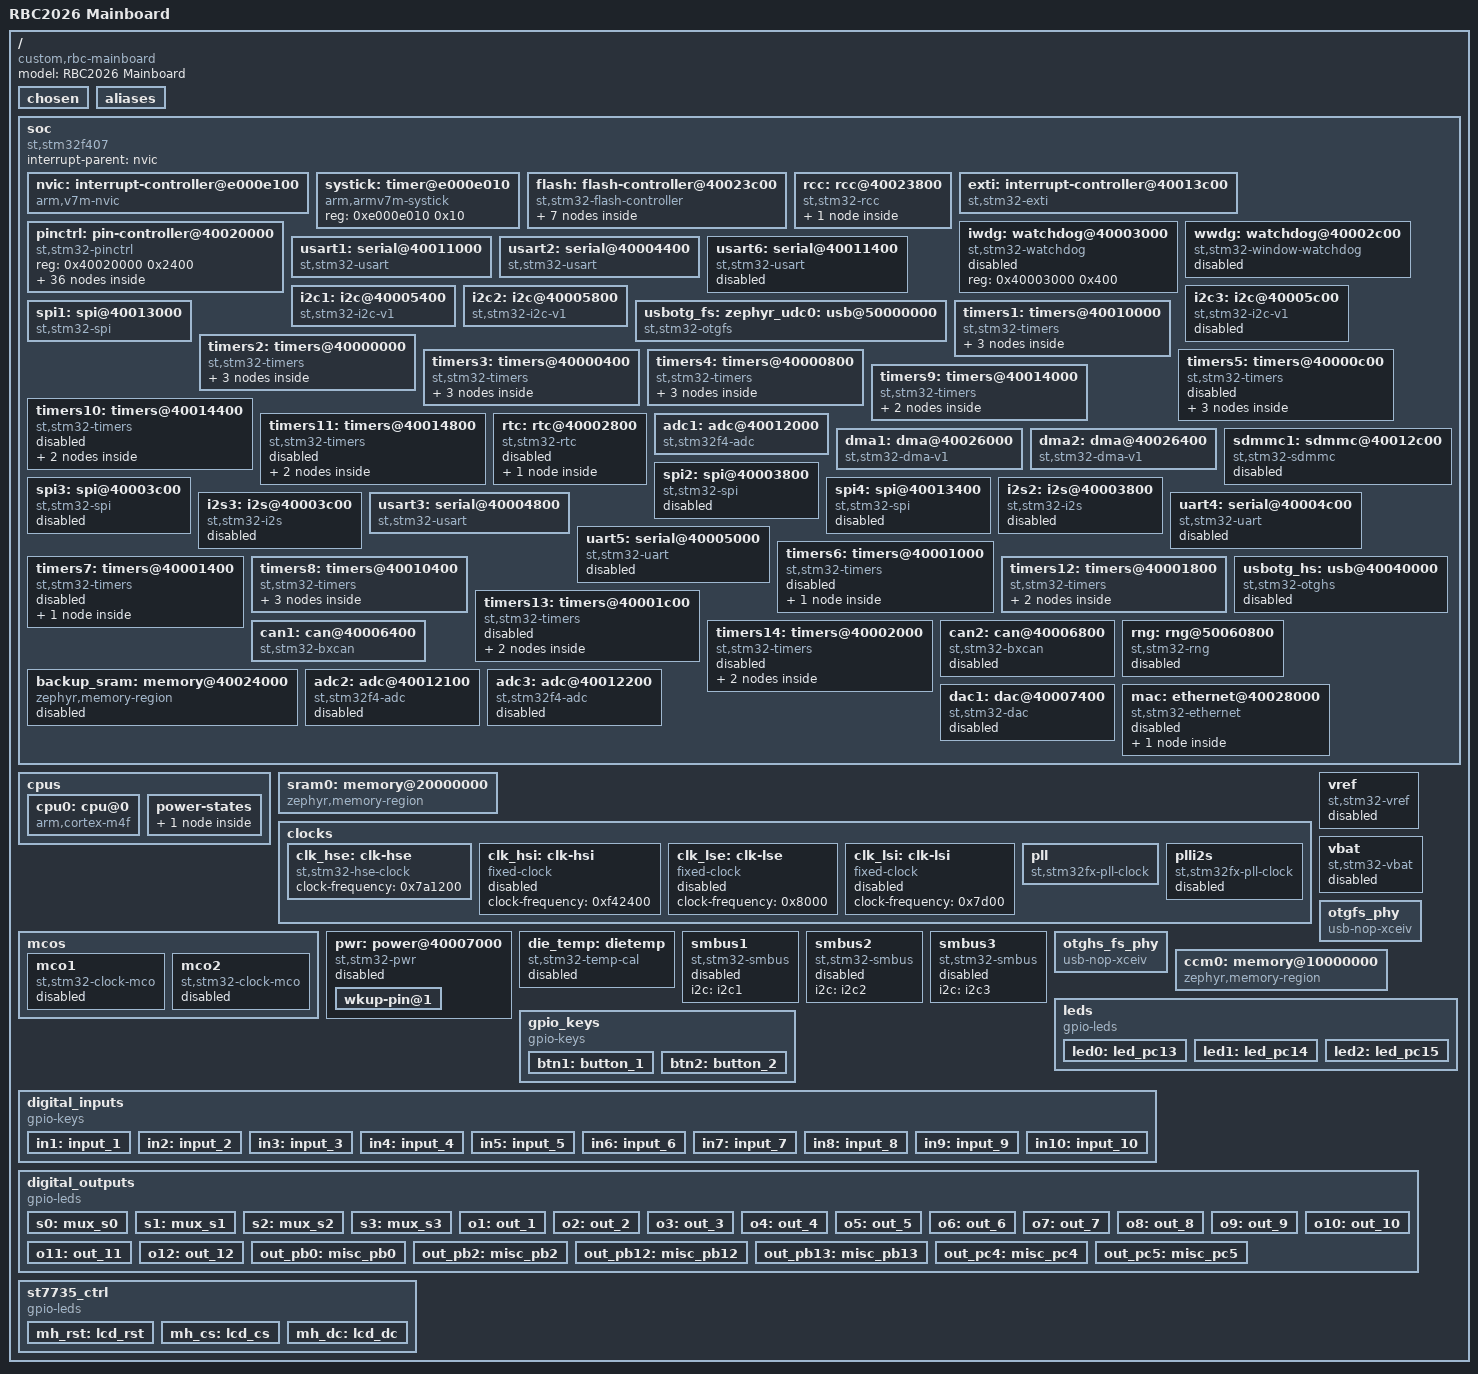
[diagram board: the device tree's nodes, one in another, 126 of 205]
/dts-v1/;

/* node '/' defined in zephyr/dts/common/skeleton.dtsi:9 */
/ {
	#address-cells = < 0x1 >;            /* in zephyr/dts/common/skeleton.dtsi:10 */
	#size-cells = < 0x1 >;               /* in zephyr/dts/common/skeleton.dtsi:11 */
	model = "RBC2026 Mainboard";         /* in rbc_main_zephyr/boards/rbc_mainboard/rbc_mainboard.dts:16 */
	compatible = "custom,rbc-mainboard"; /* in rbc_main_zephyr/boards/rbc_mainboard/rbc_mainboard.dts:17 */

	/* node '/chosen' defined in zephyr/dts/common/skeleton.dtsi:13 */
	chosen {
		zephyr,flash-controller = &flash;     /* in zephyr/dts/arm/st/f4/stm32f4.dtsi:26 */
		zephyr,system-timer-companion = &rtc; /* in zephyr/dts/arm/st/f4/stm32f4.dtsi:27 */
		zephyr,entropy = &rng;                /* in zephyr/dts/arm/st/f4/stm32f405.dtsi:13 */
		zephyr,console = &usart1;             /* in rbc_main_zephyr/boards/rbc_mainboard/rbc_mainboard.dts:20 */
		zephyr,shell-uart = &usart1;          /* in rbc_main_zephyr/boards/rbc_mainboard/rbc_mainboard.dts:21 */
		zephyr,sram = &sram0;                 /* in rbc_main_zephyr/boards/rbc_mainboard/rbc_mainboard.dts:22 */
		zephyr,flash = &flash0;               /* in rbc_main_zephyr/boards/rbc_mainboard/rbc_mainboard.dts:23 */
		zephyr,dtcm = &ccm0;                  /* in rbc_main_zephyr/boards/rbc_mainboard/rbc_mainboard.dts:24 */
		zephyr,canbus = &can1;                /* in rbc_main_zephyr/boards/rbc_mainboard/rbc_mainboard.dts:25 */
	};

	/* node '/aliases' defined in zephyr/dts/common/skeleton.dtsi:15 */
	aliases {
		led0 = &led0; /* in rbc_main_zephyr/boards/rbc_mainboard/rbc_mainboard.dts:190 */
		led1 = &led1; /* in rbc_main_zephyr/boards/rbc_mainboard/rbc_mainboard.dts:191 */
		led2 = &led2; /* in rbc_main_zephyr/boards/rbc_mainboard/rbc_mainboard.dts:192 */
		sw0 = &btn1;  /* in rbc_main_zephyr/boards/rbc_mainboard/rbc_mainboard.dts:193 */
		sw1 = &btn2;  /* in rbc_main_zephyr/boards/rbc_mainboard/rbc_mainboard.dts:194 */
	};

	/* node '/soc' defined in zephyr/dts/arm/armv7-m.dtsi:6 */
	soc {
		#address-cells = < 0x1 >;     /* in zephyr/dts/arm/armv7-m.dtsi:7 */
		#size-cells = < 0x1 >;        /* in zephyr/dts/arm/armv7-m.dtsi:8 */
		interrupt-parent = < &nvic >; /* in zephyr/dts/arm/armv7-m.dtsi:10 */
		ranges;                       /* in zephyr/dts/arm/armv7-m.dtsi:11 */
		compatible = "st,stm32f407",
		             "st,stm32f4",
		             "simple-bus";    /* in zephyr/dts/arm/st/f4/stm32f407.dtsi:11 */

		/* node '/soc/interrupt-controller@e000e100' defined in zephyr/dts/arm/armv7-m.dtsi:13 */
		nvic: interrupt-controller@e000e100 {
			#address-cells = < 0x1 >;            /* in zephyr/dts/arm/armv7-m.dtsi:14 */
			compatible = "arm,v7m-nvic";         /* in zephyr/dts/arm/armv7-m.dtsi:15 */
			reg = < 0xe000e100 0xc00 >;          /* in zephyr/dts/arm/armv7-m.dtsi:16 */
			interrupt-controller;                /* in zephyr/dts/arm/armv7-m.dtsi:17 */
			#interrupt-cells = < 0x2 >;          /* in zephyr/dts/arm/armv7-m.dtsi:18 */
			arm,num-irq-priority-bits = < 0x4 >; /* in zephyr/dts/arm/st/f4/stm32f4.dtsi:729 */
			phandle = < 0x1 >;                   /* in zephyr/dts/arm/armv7-m.dtsi:10 */
		};

		/* node '/soc/timer@e000e010' defined in zephyr/dts/arm/armv7-m.dtsi:21 */
		systick: timer@e000e010 {
			compatible = "arm,armv7m-systick"; /* in zephyr/dts/arm/armv7-m.dtsi:22 */
			reg = < 0xe000e010 0x10 >;         /* in zephyr/dts/arm/armv7-m.dtsi:23 */
		};

		/* node '/soc/flash-controller@40023c00' defined in zephyr/dts/arm/st/f4/stm32f4.dtsi:112 */
		flash: flash-controller@40023c00 {
			compatible = "st,stm32-flash-controller",
			             "st,stm32f4-flash-controller"; /* in zephyr/dts/arm/st/f4/stm32f4.dtsi:113 */
			reg = < 0x40023c00 0x400 >;                 /* in zephyr/dts/arm/st/f4/stm32f4.dtsi:114 */
			interrupts = < 0x4 0x0 >;                   /* in zephyr/dts/arm/st/f4/stm32f4.dtsi:115 */
			#address-cells = < 0x1 >;                   /* in zephyr/dts/arm/st/f4/stm32f4.dtsi:117 */
			#size-cells = < 0x1 >;                      /* in zephyr/dts/arm/st/f4/stm32f4.dtsi:118 */
			ranges;                                     /* in zephyr/dts/arm/st/f4/stm32f4.dtsi:119 */

			/* node '/soc/flash-controller@40023c00/flash@8000000' defined in zephyr/dts/arm/st/f4/stm32f4.dtsi:121 */
			flash0: flash@8000000 {
				compatible = "st,stm32f4-nv-flash",
				             "st,stm32-nv-flash",
				             "soc-nv-flash";         /* in zephyr/dts/arm/st/f4/stm32f4.dtsi:122 */
				#address-cells = < 0x1 >;            /* in zephyr/dts/arm/st/f4/stm32f4.dtsi:124 */
				#size-cells = < 0x1 >;               /* in zephyr/dts/arm/st/f4/stm32f4.dtsi:125 */
				write-block-size = < 0x1 >;          /* in zephyr/dts/arm/st/f4/stm32f4.dtsi:126 */
				max-erase-time = < 0xfa0 >;          /* in zephyr/dts/arm/st/f4/stm32f4.dtsi:128 */
				reg = < 0x8000000 0x100000 >;        /* in zephyr/dts/arm/st/f4/stm32f407Xg.dtsi:23 */
				ranges = < 0x0 0x8000000 0x100000 >; /* in zephyr/dts/arm/st/f4/stm32f407Xg.dtsi:24 */
			};

			/* node '/soc/flash-controller@40023c00/flash@1fff7800' defined in zephyr/dts/arm/st/f4/stm32f4.dtsi:131 */
			st_nvm_user_otp: flash@1fff7800 {
				compatible = "st,stm32-nvm-otp"; /* in zephyr/dts/arm/st/f4/stm32f4.dtsi:132 */
				reg = < 0x1fff7800 0x200 >;      /* in zephyr/dts/arm/st/f4/stm32f4.dtsi:133 */
				status = "disabled";             /* in zephyr/dts/arm/st/f4/stm32f4.dtsi:134 */
			};

			/* node '/soc/flash-controller@40023c00/flash@1fff7a00' defined in zephyr/dts/arm/st/f4/stm32f4.dtsi:148 */
			flash@1fff7a00 {
				compatible = "st,stm32-nvm-otp"; /* in zephyr/dts/arm/st/f4/stm32f4.dtsi:149 */
				reg = < 0x1fff7a00 0x100 >;      /* in zephyr/dts/arm/st/f4/stm32f4.dtsi:150 */

				/* node '/soc/flash-controller@40023c00/flash@1fff7a00/nvmem-layout' defined in zephyr/dts/arm/st/f4/stm32f4.dtsi:152 */
				nvmem-layout {
					compatible = "fixed-layout"; /* in zephyr/dts/arm/st/f4/stm32f4.dtsi:153 */
					#address-cells = < 0x1 >;    /* in zephyr/dts/arm/st/f4/stm32f4.dtsi:154 */
					#size-cells = < 0x1 >;       /* in zephyr/dts/arm/st/f4/stm32f4.dtsi:155 */

					/* node '/soc/flash-controller@40023c00/flash@1fff7a00/nvmem-layout/vrefint@2a' defined in zephyr/dts/arm/st/f4/stm32f4.dtsi:157 */
					vrefint_otp: vrefint@2a {
						reg = < 0x2a 0x2 >;          /* in zephyr/dts/arm/st/f4/stm32f4.dtsi:158 */
						#nvmem-cell-cells = < 0x0 >; /* in zephyr/dts/arm/st/f4/stm32f4.dtsi:159 */
						read-only;                   /* in zephyr/dts/arm/st/f4/stm32f4.dtsi:160 */
						phandle = < 0x29 >;          /* in zephyr/dts/arm/st/f4/stm32f4.dtsi:685 */
					};

					/* node '/soc/flash-controller@40023c00/flash@1fff7a00/nvmem-layout/ts-cal1@2c' defined in zephyr/dts/arm/st/f4/stm32f4.dtsi:163 */
					ts_cal1_otp: ts-cal1@2c {
						reg = < 0x2c 0x2 >;          /* in zephyr/dts/arm/st/f4/stm32f4.dtsi:164 */
						#nvmem-cell-cells = < 0x0 >; /* in zephyr/dts/arm/st/f4/stm32f4.dtsi:165 */
						read-only;                   /* in zephyr/dts/arm/st/f4/stm32f4.dtsi:166 */
						phandle = < 0x26 >;          /* in zephyr/dts/arm/st/f4/stm32f4.dtsi:674 */
					};

					/* node '/soc/flash-controller@40023c00/flash@1fff7a00/nvmem-layout/ts-cal2@2e' defined in zephyr/dts/arm/st/f4/stm32f4.dtsi:169 */
					ts_cal2_otp: ts-cal2@2e {
						reg = < 0x2e 0x2 >;          /* in zephyr/dts/arm/st/f4/stm32f4.dtsi:170 */
						#nvmem-cell-cells = < 0x0 >; /* in zephyr/dts/arm/st/f4/stm32f4.dtsi:171 */
						read-only;                   /* in zephyr/dts/arm/st/f4/stm32f4.dtsi:172 */
						phandle = < 0x27 >;          /* in zephyr/dts/arm/st/f4/stm32f4.dtsi:674 */
					};
				};
			};
		};

		/* node '/soc/rcc@40023800' defined in zephyr/dts/arm/st/f4/stm32f4.dtsi:178 */
		rcc: rcc@40023800 {
			#clock-cells = < 0x2 >;          /* in zephyr/dts/arm/st/f4/stm32f4.dtsi:180 */
			reg = < 0x40023800 0x400 >;      /* in zephyr/dts/arm/st/f4/stm32f4.dtsi:181 */
			compatible = "st,stm32-rcc";     /* in zephyr/dts/arm/st/f4/stm32f405.dtsi:20 */
			clocks = < &pll >;               /* in rbc_main_zephyr/boards/rbc_mainboard/rbc_mainboard.dts:220 */
			clock-frequency = < 0x8954400 >; /* in rbc_main_zephyr/boards/rbc_mainboard/rbc_mainboard.dts:221 */
			ahb-prescaler = < 0x1 >;         /* in rbc_main_zephyr/boards/rbc_mainboard/rbc_mainboard.dts:222 */
			apb1-prescaler = < 0x4 >;        /* in rbc_main_zephyr/boards/rbc_mainboard/rbc_mainboard.dts:223 */
			apb2-prescaler = < 0x2 >;        /* in rbc_main_zephyr/boards/rbc_mainboard/rbc_mainboard.dts:224 */
			phandle = < 0x3 >;               /* in zephyr/dts/arm/st/f4/stm32f4.dtsi:195 */

			/* node '/soc/rcc@40023800/reset-controller' defined in zephyr/dts/arm/st/f4/stm32f4.dtsi:183 */
			rctl: reset-controller {
				compatible = "st,stm32-rcc-rctl"; /* in zephyr/dts/arm/st/f4/stm32f4.dtsi:184 */
				#reset-cells = < 0x1 >;           /* in zephyr/dts/arm/st/f4/stm32f4.dtsi:185 */
				phandle = < 0x4 >;                /* in zephyr/dts/arm/st/f4/stm32f4.dtsi:294 */
			};
		};

		/* node '/soc/interrupt-controller@40013c00' defined in zephyr/dts/arm/st/f4/stm32f4.dtsi:189 */
		exti: interrupt-controller@40013c00 {
			compatible = "st,stm32-exti";  /* in zephyr/dts/arm/st/f4/stm32f4.dtsi:190 */
			interrupt-controller;          /* in zephyr/dts/arm/st/f4/stm32f4.dtsi:191 */
			#interrupt-cells = < 0x1 >;    /* in zephyr/dts/arm/st/f4/stm32f4.dtsi:192 */
			#address-cells = < 0x0 >;      /* in zephyr/dts/arm/st/f4/stm32f4.dtsi:193 */
			reg = < 0x40013c00 0x400 >;    /* in zephyr/dts/arm/st/f4/stm32f4.dtsi:194 */
			clocks = < &rcc 0x44 0x4000 >; /* in zephyr/dts/arm/st/f4/stm32f4.dtsi:195 */
			num-lines = < 0x20 >;          /* in zephyr/dts/arm/st/f4/stm32f4.dtsi:196 */
			interrupts = < 0x6 0x0 >,
			             < 0x7 0x0 >,
			             < 0x8 0x0 >,
			             < 0x9 0x0 >,
			             < 0xa 0x0 >,
			             < 0x17 0x0 >,
			             < 0x28 0x0 >;     /* in zephyr/dts/arm/st/f4/stm32f4.dtsi:197 */
			interrupt-names = "line0",
			                  "line1",
			                  "line2",
			                  "line3",
			                  "line4",
			                  "line5-9",
			                  "line10-15"; /* in zephyr/dts/arm/st/f4/stm32f4.dtsi:199 */
			line-ranges = < 0x0 0x1 >,
			              < 0x1 0x1 >,
			              < 0x2 0x1 >,
			              < 0x3 0x1 >,
			              < 0x4 0x1 >,
			              < 0x5 0x5 >,
			              < 0xa 0x6 >;     /* in zephyr/dts/arm/st/f4/stm32f4.dtsi:201 */
		};

		/* node '/soc/pin-controller@40020000' defined in zephyr/dts/arm/st/f4/stm32f4.dtsi:205 */
		pinctrl: pin-controller@40020000 {
			compatible = "st,stm32-pinctrl"; /* in zephyr/dts/arm/st/f4/stm32f4.dtsi:206 */
			#address-cells = < 0x1 >;        /* in zephyr/dts/arm/st/f4/stm32f4.dtsi:207 */
			#size-cells = < 0x1 >;           /* in zephyr/dts/arm/st/f4/stm32f4.dtsi:208 */
			reg = < 0x40020000 0x2400 >;     /* in zephyr/dts/arm/st/f4/stm32f405.dtsi:24 */

			/* node '/soc/pin-controller@40020000/gpio@40020000' defined in zephyr/dts/arm/st/f4/stm32f4.dtsi:211 */
			gpioa: gpio@40020000 {
				compatible = "st,stm32-gpio"; /* in zephyr/dts/arm/st/f4/stm32f4.dtsi:212 */
				gpio-controller;              /* in zephyr/dts/arm/st/f4/stm32f4.dtsi:213 */
				#gpio-cells = < 0x2 >;        /* in zephyr/dts/arm/st/f4/stm32f4.dtsi:214 */
				reg = < 0x40020000 0x400 >;   /* in zephyr/dts/arm/st/f4/stm32f4.dtsi:215 */
				clocks = < &rcc 0x30 0x1 >;   /* in zephyr/dts/arm/st/f4/stm32f4.dtsi:216 */
				phandle = < 0x25 >;           /* in zephyr/dts/arm/st/f4/stm32f4.dtsi:668 */
			};

			/* node '/soc/pin-controller@40020000/gpio@40020400' defined in zephyr/dts/arm/st/f4/stm32f4.dtsi:219 */
			gpiob: gpio@40020400 {
				compatible = "st,stm32-gpio"; /* in zephyr/dts/arm/st/f4/stm32f4.dtsi:220 */
				gpio-controller;              /* in zephyr/dts/arm/st/f4/stm32f4.dtsi:221 */
				#gpio-cells = < 0x2 >;        /* in zephyr/dts/arm/st/f4/stm32f4.dtsi:222 */
				reg = < 0x40020400 0x400 >;   /* in zephyr/dts/arm/st/f4/stm32f4.dtsi:223 */
				clocks = < &rcc 0x30 0x2 >;   /* in zephyr/dts/arm/st/f4/stm32f4.dtsi:224 */
				phandle = < 0x30 >;           /* in rbc_main_zephyr/boards/rbc_mainboard/rbc_mainboard.dts:103 */
			};

			/* node '/soc/pin-controller@40020000/gpio@40020800' defined in zephyr/dts/arm/st/f4/stm32f4.dtsi:227 */
			gpioc: gpio@40020800 {
				compatible = "st,stm32-gpio"; /* in zephyr/dts/arm/st/f4/stm32f4.dtsi:228 */
				gpio-controller;              /* in zephyr/dts/arm/st/f4/stm32f4.dtsi:229 */
				#gpio-cells = < 0x2 >;        /* in zephyr/dts/arm/st/f4/stm32f4.dtsi:230 */
				reg = < 0x40020800 0x400 >;   /* in zephyr/dts/arm/st/f4/stm32f4.dtsi:231 */
				clocks = < &rcc 0x30 0x4 >;   /* in zephyr/dts/arm/st/f4/stm32f4.dtsi:232 */
				phandle = < 0x2d >;           /* in rbc_main_zephyr/boards/rbc_mainboard/rbc_mainboard.dts:37 */
			};

			/* node '/soc/pin-controller@40020000/gpio@40020c00' defined in zephyr/dts/arm/st/f4/stm32f4.dtsi:235 */
			gpiod: gpio@40020c00 {
				compatible = "st,stm32-gpio"; /* in zephyr/dts/arm/st/f4/stm32f4.dtsi:236 */
				gpio-controller;              /* in zephyr/dts/arm/st/f4/stm32f4.dtsi:237 */
				#gpio-cells = < 0x2 >;        /* in zephyr/dts/arm/st/f4/stm32f4.dtsi:238 */
				reg = < 0x40020c00 0x400 >;   /* in zephyr/dts/arm/st/f4/stm32f4.dtsi:239 */
				clocks = < &rcc 0x30 0x8 >;   /* in zephyr/dts/arm/st/f4/stm32f4.dtsi:240 */
				phandle = < 0x2f >;           /* in rbc_main_zephyr/boards/rbc_mainboard/rbc_mainboard.dts:98 */
			};

			/* node '/soc/pin-controller@40020000/gpio@40021000' defined in zephyr/dts/arm/st/f4/stm32f4.dtsi:243 */
			gpioe: gpio@40021000 {
				compatible = "st,stm32-gpio"; /* in zephyr/dts/arm/st/f4/stm32f4.dtsi:244 */
				gpio-controller;              /* in zephyr/dts/arm/st/f4/stm32f4.dtsi:245 */
				#gpio-cells = < 0x2 >;        /* in zephyr/dts/arm/st/f4/stm32f4.dtsi:246 */
				reg = < 0x40021000 0x400 >;   /* in zephyr/dts/arm/st/f4/stm32f4.dtsi:247 */
				clocks = < &rcc 0x30 0x10 >;  /* in zephyr/dts/arm/st/f4/stm32f4.dtsi:248 */
				phandle = < 0x2e >;           /* in rbc_main_zephyr/boards/rbc_mainboard/rbc_mainboard.dts:62 */
			};

			/* node '/soc/pin-controller@40020000/gpio@40021400' defined in zephyr/dts/arm/st/f4/stm32f4.dtsi:251 */
			gpiof: gpio@40021400 {
				compatible = "st,stm32-gpio"; /* in zephyr/dts/arm/st/f4/stm32f405.dtsi:27 */
				gpio-controller;              /* in zephyr/dts/arm/st/f4/stm32f405.dtsi:28 */
				#gpio-cells = < 0x2 >;        /* in zephyr/dts/arm/st/f4/stm32f405.dtsi:29 */
				reg = < 0x40021400 0x400 >;   /* in zephyr/dts/arm/st/f4/stm32f405.dtsi:30 */
				clocks = < &rcc 0x30 0x20 >;  /* in zephyr/dts/arm/st/f4/stm32f405.dtsi:31 */
			};

			/* node '/soc/pin-controller@40020000/gpio@40021800' defined in zephyr/dts/arm/st/f4/stm32f4.dtsi:259 */
			gpiog: gpio@40021800 {
				compatible = "st,stm32-gpio"; /* in zephyr/dts/arm/st/f4/stm32f405.dtsi:35 */
				gpio-controller;              /* in zephyr/dts/arm/st/f4/stm32f405.dtsi:36 */
				#gpio-cells = < 0x2 >;        /* in zephyr/dts/arm/st/f4/stm32f405.dtsi:37 */
				reg = < 0x40021800 0x400 >;   /* in zephyr/dts/arm/st/f4/stm32f405.dtsi:38 */
				clocks = < &rcc 0x30 0x40 >;  /* in zephyr/dts/arm/st/f4/stm32f405.dtsi:39 */
			};

			/* node '/soc/pin-controller@40020000/gpio@40021c00' defined in zephyr/dts/arm/st/f4/stm32f4.dtsi:267 */
			gpioh: gpio@40021c00 {
				compatible = "st,stm32-gpio"; /* in zephyr/dts/arm/st/f4/stm32f4.dtsi:268 */
				gpio-controller;              /* in zephyr/dts/arm/st/f4/stm32f4.dtsi:269 */
				#gpio-cells = < 0x2 >;        /* in zephyr/dts/arm/st/f4/stm32f4.dtsi:270 */
				reg = < 0x40021c00 0x400 >;   /* in zephyr/dts/arm/st/f4/stm32f4.dtsi:271 */
				clocks = < &rcc 0x30 0x80 >;  /* in zephyr/dts/arm/st/f4/stm32f4.dtsi:272 */
			};

			/* node '/soc/pin-controller@40020000/gpio@40022000' defined in zephyr/dts/arm/st/f4/stm32f405.dtsi:42 */
			gpioi: gpio@40022000 {
				compatible = "st,stm32-gpio"; /* in zephyr/dts/arm/st/f4/stm32f405.dtsi:43 */
				gpio-controller;              /* in zephyr/dts/arm/st/f4/stm32f405.dtsi:44 */
				#gpio-cells = < 0x2 >;        /* in zephyr/dts/arm/st/f4/stm32f405.dtsi:45 */
				reg = < 0x40022000 0x400 >;   /* in zephyr/dts/arm/st/f4/stm32f405.dtsi:46 */
				clocks = < &rcc 0x30 0x100 >; /* in zephyr/dts/arm/st/f4/stm32f405.dtsi:47 */
			};

			/* node '/soc/pin-controller@40020000/adc1_in0_pa0' defined in modules/hal/stm32/dts/st/f4/stm32f407v(e-g)tx-pinctrl.dtsi:13 */
			adc1_in0_pa0: adc1_in0_pa0 {
				pinmux = < 0x10 >;  /* in modules/hal/stm32/dts/st/f4/stm32f407v(e-g)tx-pinctrl.dtsi:14 */
				phandle = < 0x1a >; /* in rbc_main_zephyr/boards/rbc_mainboard/rbc_mainboard.dts:319 */
			};

			/* node '/soc/pin-controller@40020000/can1_rx_pd0' defined in modules/hal/stm32/dts/st/f4/stm32f407v(e-g)tx-pinctrl.dtsi:515 */
			can1_rx_pd0: can1_rx_pd0 {
				pinmux = < 0x609 >; /* in modules/hal/stm32/dts/st/f4/stm32f407v(e-g)tx-pinctrl.dtsi:516 */
				bias-pull-up;       /* in modules/hal/stm32/dts/st/f4/stm32f407v(e-g)tx-pinctrl.dtsi:517 */
				phandle = < 0x21 >; /* in rbc_main_zephyr/boards/rbc_mainboard/rbc_mainboard.dts:270 */
			};

			/* node '/soc/pin-controller@40020000/can1_tx_pd1' defined in modules/hal/stm32/dts/st/f4/stm32f407v(e-g)tx-pinctrl.dtsi:540 */
			can1_tx_pd1: can1_tx_pd1 {
				pinmux = < 0x629 >; /* in modules/hal/stm32/dts/st/f4/stm32f407v(e-g)tx-pinctrl.dtsi:541 */
				phandle = < 0x22 >; /* in rbc_main_zephyr/boards/rbc_mainboard/rbc_mainboard.dts:270 */
			};

			/* node '/soc/pin-controller@40020000/i2c1_scl_pb6' defined in modules/hal/stm32/dts/st/f4/stm32f407v(e-g)tx-pinctrl.dtsi:783 */
			i2c1_scl_pb6: i2c1_scl_pb6 {
				pinmux = < 0x2c4 >; /* in modules/hal/stm32/dts/st/f4/stm32f407v(e-g)tx-pinctrl.dtsi:784 */
				bias-pull-up;       /* in modules/hal/stm32/dts/st/f4/stm32f407v(e-g)tx-pinctrl.dtsi:785 */
				drive-open-drain;   /* in modules/hal/stm32/dts/st/f4/stm32f407v(e-g)tx-pinctrl.dtsi:786 */
				phandle = < 0x9 >;  /* in rbc_main_zephyr/boards/rbc_mainboard/rbc_mainboard.dts:284 */
			};

			/* node '/soc/pin-controller@40020000/i2c2_scl_pb10' defined in modules/hal/stm32/dts/st/f4/stm32f407v(e-g)tx-pinctrl.dtsi:795 */
			i2c2_scl_pb10: i2c2_scl_pb10 {
				pinmux = < 0x344 >; /* in modules/hal/stm32/dts/st/f4/stm32f407v(e-g)tx-pinctrl.dtsi:796 */
				bias-pull-up;       /* in modules/hal/stm32/dts/st/f4/stm32f407v(e-g)tx-pinctrl.dtsi:797 */
				drive-open-drain;   /* in modules/hal/stm32/dts/st/f4/stm32f407v(e-g)tx-pinctrl.dtsi:798 */
				phandle = < 0xb >;  /* in rbc_main_zephyr/boards/rbc_mainboard/rbc_mainboard.dts:296 */
			};

			/* node '/soc/pin-controller@40020000/i2c1_sda_pb7' defined in modules/hal/stm32/dts/st/f4/stm32f407v(e-g)tx-pinctrl.dtsi:809 */
			i2c1_sda_pb7: i2c1_sda_pb7 {
				pinmux = < 0x2e4 >; /* in modules/hal/stm32/dts/st/f4/stm32f407v(e-g)tx-pinctrl.dtsi:810 */
				bias-pull-up;       /* in modules/hal/stm32/dts/st/f4/stm32f407v(e-g)tx-pinctrl.dtsi:811 */
				drive-open-drain;   /* in modules/hal/stm32/dts/st/f4/stm32f407v(e-g)tx-pinctrl.dtsi:812 */
				phandle = < 0xa >;  /* in rbc_main_zephyr/boards/rbc_mainboard/rbc_mainboard.dts:284 */
			};

			/* node '/soc/pin-controller@40020000/i2c2_sda_pb11' defined in modules/hal/stm32/dts/st/f4/stm32f407v(e-g)tx-pinctrl.dtsi:821 */
			i2c2_sda_pb11: i2c2_sda_pb11 {
				pinmux = < 0x364 >; /* in modules/hal/stm32/dts/st/f4/stm32f407v(e-g)tx-pinctrl.dtsi:822 */
				bias-pull-up;       /* in modules/hal/stm32/dts/st/f4/stm32f407v(e-g)tx-pinctrl.dtsi:823 */
				drive-open-drain;   /* in modules/hal/stm32/dts/st/f4/stm32f407v(e-g)tx-pinctrl.dtsi:824 */
				phandle = < 0xc >;  /* in rbc_main_zephyr/boards/rbc_mainboard/rbc_mainboard.dts:296 */
			};

			/* node '/soc/pin-controller@40020000/spi1_miso_pa6' defined in modules/hal/stm32/dts/st/f4/stm32f407v(e-g)tx-pinctrl.dtsi:1018 */
			spi1_miso_pa6: spi1_miso_pa6 {
				pinmux = < 0xc5 >;             /* in modules/hal/stm32/dts/st/f4/stm32f407v(e-g)tx-pinctrl.dtsi:1019 */
				bias-pull-down;                /* in modules/hal/stm32/dts/st/f4/stm32f407v(e-g)tx-pinctrl.dtsi:1020 */
				slew-rate = "very-high-speed"; /* in modules/hal/stm32/dts/st/f4/stm32f407v(e-g)tx-pinctrl.dtsi:1021 */
				phandle = < 0xe >;             /* in rbc_main_zephyr/boards/rbc_mainboard/rbc_mainboard.dts:308 */
			};

			/* node '/soc/pin-controller@40020000/spi1_mosi_pa7' defined in modules/hal/stm32/dts/st/f4/stm32f407v(e-g)tx-pinctrl.dtsi:1056 */
			spi1_mosi_pa7: spi1_mosi_pa7 {
				pinmux = < 0xe5 >;             /* in modules/hal/stm32/dts/st/f4/stm32f407v(e-g)tx-pinctrl.dtsi:1057 */
				bias-pull-down;                /* in modules/hal/stm32/dts/st/f4/stm32f407v(e-g)tx-pinctrl.dtsi:1058 */
				slew-rate = "very-high-speed"; /* in modules/hal/stm32/dts/st/f4/stm32f407v(e-g)tx-pinctrl.dtsi:1059 */
				phandle = < 0xf >;             /* in rbc_main_zephyr/boards/rbc_mainboard/rbc_mainboard.dts:308 */
			};

			/* node '/soc/pin-controller@40020000/spi1_sck_pa5' defined in modules/hal/stm32/dts/st/f4/stm32f407v(e-g)tx-pinctrl.dtsi:1132 */
			spi1_sck_pa5: spi1_sck_pa5 {
				pinmux = < 0xa5 >;             /* in modules/hal/stm32/dts/st/f4/stm32f407v(e-g)tx-pinctrl.dtsi:1133 */
				bias-pull-down;                /* in modules/hal/stm32/dts/st/f4/stm32f407v(e-g)tx-pinctrl.dtsi:1134 */
				slew-rate = "very-high-speed"; /* in modules/hal/stm32/dts/st/f4/stm32f407v(e-g)tx-pinctrl.dtsi:1135 */
				phandle = < 0xd >;             /* in rbc_main_zephyr/boards/rbc_mainboard/rbc_mainboard.dts:308 */
			};

			/* node '/soc/pin-controller@40020000/tim2_ch1_pa15' defined in modules/hal/stm32/dts/st/f4/stm32f407v(e-g)tx-pinctrl.dtsi:1284 */
			tim2_ch1_pa15: tim2_ch1_pa15 {
				pinmux = < 0x1e1 >; /* in modules/hal/stm32/dts/st/f4/stm32f407v(e-g)tx-pinctrl.dtsi:1285 */
				phandle = < 0x13 >; /* in rbc_main_zephyr/boards/rbc_mainboard/rbc_mainboard.dts:338 */
			};

			/* node '/soc/pin-controller@40020000/tim2_ch2_pb3' defined in modules/hal/stm32/dts/st/f4/stm32f407v(e-g)tx-pinctrl.dtsi:1288 */
			tim2_ch2_pb3: tim2_ch2_pb3 {
				pinmux = < 0x261 >; /* in modules/hal/stm32/dts/st/f4/stm32f407v(e-g)tx-pinctrl.dtsi:1289 */
				phandle = < 0x14 >; /* in rbc_main_zephyr/boards/rbc_mainboard/rbc_mainboard.dts:338 */
			};

			/* node '/soc/pin-controller@40020000/tim12_ch1_pb14' defined in modules/hal/stm32/dts/st/f4/stm32f407v(e-g)tx-pinctrl.dtsi:1300 */
			tim12_ch1_pb14: tim12_ch1_pb14 {
				pinmux = < 0x3c9 >; /* in modules/hal/stm32/dts/st/f4/stm32f407v(e-g)tx-pinctrl.dtsi:1301 */
				phandle = < 0x1e >; /* in rbc_main_zephyr/boards/rbc_mainboard/rbc_mainboard.dts:436 */
			};

			/* node '/soc/pin-controller@40020000/tim12_ch2_pb15' defined in modules/hal/stm32/dts/st/f4/stm32f407v(e-g)tx-pinctrl.dtsi:1304 */
			tim12_ch2_pb15: tim12_ch2_pb15 {
				pinmux = < 0x3e9 >; /* in modules/hal/stm32/dts/st/f4/stm32f407v(e-g)tx-pinctrl.dtsi:1305 */
				phandle = < 0x1f >; /* in rbc_main_zephyr/boards/rbc_mainboard/rbc_mainboard.dts:436 */
			};

			/* node '/soc/pin-controller@40020000/tim3_ch1_pc6' defined in modules/hal/stm32/dts/st/f4/stm32f407v(e-g)tx-pinctrl.dtsi:1336 */
			tim3_ch1_pc6: tim3_ch1_pc6 {
				pinmux = < 0x4c2 >; /* in modules/hal/stm32/dts/st/f4/stm32f407v(e-g)tx-pinctrl.dtsi:1337 */
				phandle = < 0x15 >; /* in rbc_main_zephyr/boards/rbc_mainboard/rbc_mainboard.dts:353 */
			};

			/* node '/soc/pin-controller@40020000/tim3_ch2_pc7' defined in modules/hal/stm32/dts/st/f4/stm32f407v(e-g)tx-pinctrl.dtsi:1340 */
			tim3_ch2_pc7: tim3_ch2_pc7 {
				pinmux = < 0x4e2 >; /* in modules/hal/stm32/dts/st/f4/stm32f407v(e-g)tx-pinctrl.dtsi:1341 */
				phandle = < 0x16 >; /* in rbc_main_zephyr/boards/rbc_mainboard/rbc_mainboard.dts:353 */
			};

			/* node '/soc/pin-controller@40020000/tim4_ch1_pd12' defined in modules/hal/stm32/dts/st/f4/stm32f407v(e-g)tx-pinctrl.dtsi:1372 */
			tim4_ch1_pd12: tim4_ch1_pd12 {
				pinmux = < 0x782 >; /* in modules/hal/stm32/dts/st/f4/stm32f407v(e-g)tx-pinctrl.dtsi:1373 */
				phandle = < 0x17 >; /* in rbc_main_zephyr/boards/rbc_mainboard/rbc_mainboard.dts:368 */
			};

			/* node '/soc/pin-controller@40020000/tim4_ch2_pd13' defined in modules/hal/stm32/dts/st/f4/stm32f407v(e-g)tx-pinctrl.dtsi:1376 */
			tim4_ch2_pd13: tim4_ch2_pd13 {
				pinmux = < 0x7a2 >; /* in modules/hal/stm32/dts/st/f4/stm32f407v(e-g)tx-pinctrl.dtsi:1377 */
				phandle = < 0x18 >; /* in rbc_main_zephyr/boards/rbc_mainboard/rbc_mainboard.dts:368 */
			};

			/* node '/soc/pin-controller@40020000/tim9_ch2_pe6' defined in modules/hal/stm32/dts/st/f4/stm32f407v(e-g)tx-pinctrl.dtsi:1456 */
			tim9_ch2_pe6: tim9_ch2_pe6 {
				pinmux = < 0x8c3 >; /* in modules/hal/stm32/dts/st/f4/stm32f407v(e-g)tx-pinctrl.dtsi:1457 */
				phandle = < 0x19 >; /* in rbc_main_zephyr/boards/rbc_mainboard/rbc_mainboard.dts:419 */
			};

			/* node '/soc/pin-controller@40020000/usart1_rx_pa10' defined in modules/hal/stm32/dts/st/f4/stm32f407v(e-g)tx-pinctrl.dtsi:1516 */
			usart1_rx_pa10: usart1_rx_pa10 {
				pinmux = < 0x147 >; /* in modules/hal/stm32/dts/st/f4/stm32f407v(e-g)tx-pinctrl.dtsi:1517 */
				phandle = < 0x6 >;  /* in rbc_main_zephyr/boards/rbc_mainboard/rbc_mainboard.dts:233 */
			};

			/* node '/soc/pin-controller@40020000/usart2_rx_pd6' defined in modules/hal/stm32/dts/st/f4/stm32f407v(e-g)tx-pinctrl.dtsi:1528 */
			usart2_rx_pd6: usart2_rx_pd6 {
				pinmux = < 0x6c7 >; /* in modules/hal/stm32/dts/st/f4/stm32f407v(e-g)tx-pinctrl.dtsi:1529 */
				phandle = < 0x8 >;  /* in rbc_main_zephyr/boards/rbc_mainboard/rbc_mainboard.dts:245 */
			};

			/* node '/soc/pin-controller@40020000/usart3_rx_pd9' defined in modules/hal/stm32/dts/st/f4/stm32f407v(e-g)tx-pinctrl.dtsi:1540 */
			usart3_rx_pd9: usart3_rx_pd9 {
				pinmux = < 0x727 >; /* in modules/hal/stm32/dts/st/f4/stm32f407v(e-g)tx-pinctrl.dtsi:1541 */
				phandle = < 0x1d >; /* in rbc_main_zephyr/boards/rbc_mainboard/rbc_mainboard.dts:257 */
			};

			/* node '/soc/pin-controller@40020000/usart1_tx_pa9' defined in modules/hal/stm32/dts/st/f4/stm32f407v(e-g)tx-pinctrl.dtsi:1562 */
			usart1_tx_pa9: usart1_tx_pa9 {
				pinmux = < 0x127 >; /* in modules/hal/stm32/dts/st/f4/stm32f407v(e-g)tx-pinctrl.dtsi:1563 */
				bias-pull-up;       /* in modules/hal/stm32/dts/st/f4/stm32f407v(e-g)tx-pinctrl.dtsi:1564 */
				phandle = < 0x5 >;  /* in rbc_main_zephyr/boards/rbc_mainboard/rbc_mainboard.dts:233 */
			};

			/* node '/soc/pin-controller@40020000/usart2_tx_pd5' defined in modules/hal/stm32/dts/st/f4/stm32f407v(e-g)tx-pinctrl.dtsi:1577 */
			usart2_tx_pd5: usart2_tx_pd5 {
				pinmux = < 0x6a7 >; /* in modules/hal/stm32/dts/st/f4/stm32f407v(e-g)tx-pinctrl.dtsi:1578 */
				bias-pull-up;       /* in modules/hal/stm32/dts/st/f4/stm32f407v(e-g)tx-pinctrl.dtsi:1579 */
				phandle = < 0x7 >;  /* in rbc_main_zephyr/boards/rbc_mainboard/rbc_mainboard.dts:245 */
			};

			/* node '/soc/pin-controller@40020000/usart3_tx_pd8' defined in modules/hal/stm32/dts/st/f4/stm32f407v(e-g)tx-pinctrl.dtsi:1592 */
			usart3_tx_pd8: usart3_tx_pd8 {
				pinmux = < 0x707 >; /* in modules/hal/stm32/dts/st/f4/stm32f407v(e-g)tx-pinctrl.dtsi:1593 */
				bias-pull-up;       /* in modules/hal/stm32/dts/st/f4/stm32f407v(e-g)tx-pinctrl.dtsi:1594 */
				phandle = < 0x1c >; /* in rbc_main_zephyr/boards/rbc_mainboard/rbc_mainboard.dts:257 */
			};

			/* node '/soc/pin-controller@40020000/usb_otg_fs_dm_pa11' defined in modules/hal/stm32/dts/st/f4/stm32f407v(e-g)tx-pinctrl.dtsi:1631 */
			usb_otg_fs_dm_pa11: usb_otg_fs_dm_pa11 {
				pinmux = < 0x16a >; /* in modules/hal/stm32/dts/st/f4/stm32f407v(e-g)tx-pinctrl.dtsi:1632 */
				phandle = < 0x11 >; /* in rbc_main_zephyr/boards/rbc_mainboard/rbc_mainboard.dts:448 */
			};

			/* node '/soc/pin-controller@40020000/usb_otg_fs_dp_pa12' defined in modules/hal/stm32/dts/st/f4/stm32f407v(e-g)tx-pinctrl.dtsi:1635 */
			usb_otg_fs_dp_pa12: usb_otg_fs_dp_pa12 {
				pinmux = < 0x18a >; /* in modules/hal/stm32/dts/st/f4/stm32f407v(e-g)tx-pinctrl.dtsi:1636 */
				phandle = < 0x12 >; /* in rbc_main_zephyr/boards/rbc_mainboard/rbc_mainboard.dts:448 */
			};
		};

		/* node '/soc/watchdog@40003000' defined in zephyr/dts/arm/st/f4/stm32f4.dtsi:276 */
		iwdg: watchdog@40003000 {
			compatible = "st,stm32-watchdog"; /* in zephyr/dts/arm/st/f4/stm32f4.dtsi:277 */
			reg = < 0x40003000 0x400 >;       /* in zephyr/dts/arm/st/f4/stm32f4.dtsi:278 */
			status = "disabled";              /* in zephyr/dts/arm/st/f4/stm32f4.dtsi:279 */
		};

		/* node '/soc/watchdog@40002c00' defined in zephyr/dts/arm/st/f4/stm32f4.dtsi:282 */
		wwdg: watchdog@40002c00 {
			compatible = "st,stm32-window-watchdog"; /* in zephyr/dts/arm/st/f4/stm32f4.dtsi:283 */
			reg = < 0x40002c00 0x400 >;              /* in zephyr/dts/arm/st/f4/stm32f4.dtsi:284 */
			clocks = < &rcc 0x40 0x800 >;            /* in zephyr/dts/arm/st/f4/stm32f4.dtsi:285 */
			interrupts = < 0x0 0x0 >;                /* in zephyr/dts/arm/st/f4/stm32f4.dtsi:286 */
			status = "disabled";                     /* in zephyr/dts/arm/st/f4/stm32f4.dtsi:287 */
		};

		/* node '/soc/serial@40011000' defined in zephyr/dts/arm/st/f4/stm32f4.dtsi:290 */
		usart1: serial@40011000 {
			compatible = "st,stm32-usart",
			             "st,stm32-uart";                   /* in zephyr/dts/arm/st/f4/stm32f4.dtsi:291 */
			reg = < 0x40011000 0x400 >;                     /* in zephyr/dts/arm/st/f4/stm32f4.dtsi:292 */
			clocks = < &rcc 0x44 0x10 >;                    /* in zephyr/dts/arm/st/f4/stm32f4.dtsi:293 */
			resets = < &rctl 0x484 >;                       /* in zephyr/dts/arm/st/f4/stm32f4.dtsi:294 */
			interrupts = < 0x25 0x0 >;                      /* in zephyr/dts/arm/st/f4/stm32f4.dtsi:295 */
			pinctrl-0 = < &usart1_tx_pa9 &usart1_rx_pa10 >; /* in rbc_main_zephyr/boards/rbc_mainboard/rbc_mainboard.dts:233 */
			pinctrl-names = "default";                      /* in rbc_main_zephyr/boards/rbc_mainboard/rbc_mainboard.dts:234 */
			current-speed = < 0x1c200 >;                    /* in rbc_main_zephyr/boards/rbc_mainboard/rbc_mainboard.dts:235 */
			status = "okay";                                /* in rbc_main_zephyr/boards/rbc_mainboard/rbc_mainboard.dts:236 */
		};

		/* node '/soc/serial@40004400' defined in zephyr/dts/arm/st/f4/stm32f4.dtsi:299 */
		usart2: serial@40004400 {
			compatible = "st,stm32-usart",
			             "st,stm32-uart";                  /* in zephyr/dts/arm/st/f4/stm32f4.dtsi:300 */
			reg = < 0x40004400 0x400 >;                    /* in zephyr/dts/arm/st/f4/stm32f4.dtsi:301 */
			clocks = < &rcc 0x40 0x20000 >;                /* in zephyr/dts/arm/st/f4/stm32f4.dtsi:302 */
			resets = < &rctl 0x411 >;                      /* in zephyr/dts/arm/st/f4/stm32f4.dtsi:303 */
			interrupts = < 0x26 0x0 >;                     /* in zephyr/dts/arm/st/f4/stm32f4.dtsi:304 */
			pinctrl-0 = < &usart2_tx_pd5 &usart2_rx_pd6 >; /* in rbc_main_zephyr/boards/rbc_mainboard/rbc_mainboard.dts:245 */
			pinctrl-names = "default";                     /* in rbc_main_zephyr/boards/rbc_mainboard/rbc_mainboard.dts:246 */
			current-speed = < 0x1c200 >;                   /* in rbc_main_zephyr/boards/rbc_mainboard/rbc_mainboard.dts:247 */
			status = "okay";                               /* in rbc_main_zephyr/boards/rbc_mainboard/rbc_mainboard.dts:248 */
		};

		/* node '/soc/serial@40011400' defined in zephyr/dts/arm/st/f4/stm32f4.dtsi:308 */
		usart6: serial@40011400 {
			compatible = "st,stm32-usart",
			             "st,stm32-uart";  /* in zephyr/dts/arm/st/f4/stm32f4.dtsi:309 */
			reg = < 0x40011400 0x400 >;    /* in zephyr/dts/arm/st/f4/stm32f4.dtsi:310 */
			clocks = < &rcc 0x44 0x20 >;   /* in zephyr/dts/arm/st/f4/stm32f4.dtsi:311 */
			resets = < &rctl 0x485 >;      /* in zephyr/dts/arm/st/f4/stm32f4.dtsi:312 */
			interrupts = < 0x47 0x0 >;     /* in zephyr/dts/arm/st/f4/stm32f4.dtsi:313 */
			status = "disabled";           /* in zephyr/dts/arm/st/f4/stm32f4.dtsi:314 */
		};

		/* node '/soc/i2c@40005400' defined in zephyr/dts/arm/st/f4/stm32f4.dtsi:317 */
		i2c1: i2c@40005400 {
			compatible = "st,stm32-i2c-v1";              /* in zephyr/dts/arm/st/f4/stm32f4.dtsi:318 */
			#address-cells = < 0x1 >;                    /* in zephyr/dts/arm/st/f4/stm32f4.dtsi:320 */
			#size-cells = < 0x0 >;                       /* in zephyr/dts/arm/st/f4/stm32f4.dtsi:321 */
			reg = < 0x40005400 0x400 >;                  /* in zephyr/dts/arm/st/f4/stm32f4.dtsi:322 */
			clocks = < &rcc 0x40 0x200000 >;             /* in zephyr/dts/arm/st/f4/stm32f4.dtsi:323 */
			interrupts = < 0x1f 0x0 >,
			             < 0x20 0x0 >;                   /* in zephyr/dts/arm/st/f4/stm32f4.dtsi:324 */
			interrupt-names = "event",
			                  "error";                   /* in zephyr/dts/arm/st/f4/stm32f4.dtsi:325 */
			pinctrl-0 = < &i2c1_scl_pb6 &i2c1_sda_pb7 >; /* in rbc_main_zephyr/boards/rbc_mainboard/rbc_mainboard.dts:284 */
			pinctrl-names = "default";                   /* in rbc_main_zephyr/boards/rbc_mainboard/rbc_mainboard.dts:285 */
			clock-frequency = < 0x61a80 >;               /* in rbc_main_zephyr/boards/rbc_mainboard/rbc_mainboard.dts:286 */
			status = "okay";                             /* in rbc_main_zephyr/boards/rbc_mainboard/rbc_mainboard.dts:287 */
			phandle = < 0x2a >;                          /* in zephyr/dts/arm/st/f4/stm32f4.dtsi:707 */
		};

		/* node '/soc/i2c@40005800' defined in zephyr/dts/arm/st/f4/stm32f4.dtsi:329 */
		i2c2: i2c@40005800 {
			compatible = "st,stm32-i2c-v1";                /* in zephyr/dts/arm/st/f4/stm32f4.dtsi:330 */
			#address-cells = < 0x1 >;                      /* in zephyr/dts/arm/st/f4/stm32f4.dtsi:332 */
			#size-cells = < 0x0 >;                         /* in zephyr/dts/arm/st/f4/stm32f4.dtsi:333 */
			reg = < 0x40005800 0x400 >;                    /* in zephyr/dts/arm/st/f4/stm32f4.dtsi:334 */
			clocks = < &rcc 0x40 0x400000 >;               /* in zephyr/dts/arm/st/f4/stm32f4.dtsi:335 */
			interrupts = < 0x21 0x0 >,
			             < 0x22 0x0 >;                     /* in zephyr/dts/arm/st/f4/stm32f4.dtsi:336 */
			interrupt-names = "event",
			                  "error";                     /* in zephyr/dts/arm/st/f4/stm32f4.dtsi:337 */
			pinctrl-0 = < &i2c2_scl_pb10 &i2c2_sda_pb11 >; /* in rbc_main_zephyr/boards/rbc_mainboard/rbc_mainboard.dts:296 */
			pinctrl-names = "default";                     /* in rbc_main_zephyr/boards/rbc_mainboard/rbc_mainboard.dts:297 */
			clock-frequency = < 0x61a80 >;                 /* in rbc_main_zephyr/boards/rbc_mainboard/rbc_mainboard.dts:298 */
			status = "okay";                               /* in rbc_main_zephyr/boards/rbc_mainboard/rbc_mainboard.dts:299 */
			phandle = < 0x2b >;                            /* in zephyr/dts/arm/st/f4/stm32f4.dtsi:715 */
		};

		/* node '/soc/i2c@40005c00' defined in zephyr/dts/arm/st/f4/stm32f4.dtsi:341 */
		i2c3: i2c@40005c00 {
			compatible = "st,stm32-i2c-v1";  /* in zephyr/dts/arm/st/f4/stm32f4.dtsi:342 */
			clock-frequency = < 0x186a0 >;   /* in zephyr/dts/arm/st/f4/stm32f4.dtsi:343 */
			#address-cells = < 0x1 >;        /* in zephyr/dts/arm/st/f4/stm32f4.dtsi:344 */
			#size-cells = < 0x0 >;           /* in zephyr/dts/arm/st/f4/stm32f4.dtsi:345 */
			reg = < 0x40005c00 0x400 >;      /* in zephyr/dts/arm/st/f4/stm32f4.dtsi:346 */
			clocks = < &rcc 0x40 0x800000 >; /* in zephyr/dts/arm/st/f4/stm32f4.dtsi:347 */
			interrupts = < 0x48 0x0 >,
			             < 0x49 0x0 >;       /* in zephyr/dts/arm/st/f4/stm32f4.dtsi:348 */
			interrupt-names = "event",
			                  "error";       /* in zephyr/dts/arm/st/f4/stm32f4.dtsi:349 */
			status = "disabled";             /* in zephyr/dts/arm/st/f4/stm32f4.dtsi:350 */
			phandle = < 0x2c >;              /* in zephyr/dts/arm/st/f4/stm32f4.dtsi:723 */
		};

		/* node '/soc/spi@40013000' defined in zephyr/dts/arm/st/f4/stm32f4.dtsi:353 */
		spi1: spi@40013000 {
			compatible = "st,stm32-spi";                                 /* in zephyr/dts/arm/st/f4/stm32f4.dtsi:354 */
			#address-cells = < 0x1 >;                                    /* in zephyr/dts/arm/st/f4/stm32f4.dtsi:355 */
			#size-cells = < 0x0 >;                                       /* in zephyr/dts/arm/st/f4/stm32f4.dtsi:356 */
			reg = < 0x40013000 0x400 >;                                  /* in zephyr/dts/arm/st/f4/stm32f4.dtsi:357 */
			clocks = < &rcc 0x44 0x1000 >;                               /* in zephyr/dts/arm/st/f4/stm32f4.dtsi:358 */
			interrupts = < 0x23 0x0 >;                                   /* in zephyr/dts/arm/st/f4/stm32f4.dtsi:359 */
			st,spi-data-width = "limited-8-16-bit";                      /* in zephyr/dts/arm/st/f4/stm32f4.dtsi:360 */
			pinctrl-0 = < &spi1_sck_pa5 &spi1_miso_pa6 &spi1_mosi_pa7 >; /* in rbc_main_zephyr/boards/rbc_mainboard/rbc_mainboard.dts:308 */
			pinctrl-names = "default";                                   /* in rbc_main_zephyr/boards/rbc_mainboard/rbc_mainboard.dts:309 */
			status = "okay";                                             /* in rbc_main_zephyr/boards/rbc_mainboard/rbc_mainboard.dts:310 */
		};

		/* node '/soc/usb@50000000' defined in zephyr/dts/arm/st/f4/stm32f4.dtsi:364 */
		usbotg_fs: zephyr_udc0: usb@50000000 {
			compatible = "st,stm32-otgfs";                           /* in zephyr/dts/arm/st/f4/stm32f4.dtsi:365 */
			reg = < 0x50000000 0x40000 >;                            /* in zephyr/dts/arm/st/f4/stm32f4.dtsi:366 */
			interrupts = < 0x43 0x0 >;                               /* in zephyr/dts/arm/st/f4/stm32f4.dtsi:367 */
			interrupt-names = "otgfs";                               /* in zephyr/dts/arm/st/f4/stm32f4.dtsi:368 */
			num-bidir-endpoints = < 0x4 >;                           /* in zephyr/dts/arm/st/f4/stm32f4.dtsi:369 */
			ram-size = < 0x500 >;                                    /* in zephyr/dts/arm/st/f4/stm32f4.dtsi:370 */
			maximum-speed = "full-speed";                            /* in zephyr/dts/arm/st/f4/stm32f4.dtsi:371 */
			phys = < &otgfs_phy >;                                   /* in zephyr/dts/arm/st/f4/stm32f4.dtsi:372 */
			clocks = < &rcc 0x34 0x80 >,
			         < &rcc 0x7 0xff >;                              /* in zephyr/dts/arm/st/f4/stm32f4.dtsi:373 */
			pinctrl-0 = < &usb_otg_fs_dm_pa11 &usb_otg_fs_dp_pa12 >; /* in rbc_main_zephyr/boards/rbc_mainboard/rbc_mainboard.dts:448 */
			pinctrl-names = "default";                               /* in rbc_main_zephyr/boards/rbc_mainboard/rbc_mainboard.dts:449 */
			status = "okay";                                         /* in rbc_main_zephyr/boards/rbc_mainboard/rbc_mainboard.dts:450 */
		};

		/* node '/soc/timers@40010000' defined in zephyr/dts/arm/st/f4/stm32f4.dtsi:378 */
		timers1: timers@40010000 {
			compatible = "st,stm32-timers"; /* in zephyr/dts/arm/st/f4/stm32f4.dtsi:379 */
			reg = < 0x40010000 0x400 >;     /* in zephyr/dts/arm/st/f4/stm32f4.dtsi:380 */
			clocks = < &rcc 0x44 0x1 >,
			         < &rcc 0x16 0xff >;    /* in zephyr/dts/arm/st/f4/stm32f4.dtsi:381 */
			resets = < &rctl 0x480 >;       /* in zephyr/dts/arm/st/f4/stm32f4.dtsi:383 */
			interrupts = < 0x18 0x0 >,
			             < 0x19 0x0 >,
			             < 0x1a 0x0 >,
			             < 0x1b 0x0 >;      /* in zephyr/dts/arm/st/f4/stm32f4.dtsi:384 */
			interrupt-names = "brk",
			                  "up",
			                  "trgcom",
			                  "cc";         /* in zephyr/dts/arm/st/f4/stm32f4.dtsi:385 */
			status = "okay";                /* in rbc_main_zephyr/boards/rbc_mainboard/rbc_mainboard.dts:383 */
			st,prescaler = < 0x8f >;        /* in rbc_main_zephyr/boards/rbc_mainboard/rbc_mainboard.dts:384 */

			/* node '/soc/timers@40010000/pwm' defined in zephyr/dts/arm/st/f4/stm32f4.dtsi:389 */
			pwm {
				compatible = "st,stm32-pwm"; /* in zephyr/dts/arm/st/f4/stm32f4.dtsi:390 */
				status = "disabled";         /* in zephyr/dts/arm/st/f4/stm32f4.dtsi:391 */
				#pwm-cells = < 0x3 >;        /* in zephyr/dts/arm/st/f4/stm32f4.dtsi:392 */
			};

			/* node '/soc/timers@40010000/counter' defined in zephyr/dts/arm/st/f4/stm32f4.dtsi:395 */
			counter1: counter {
				compatible = "st,stm32-counter"; /* in rbc_main_zephyr/boards/rbc_mainboard/rbc_mainboard.dts:387 */
				status = "okay";                 /* in rbc_main_zephyr/boards/rbc_mainboard/rbc_mainboard.dts:388 */
			};

			/* node '/soc/timers@40010000/qdec' defined in zephyr/dts/arm/st/f4/stm32f4.dtsi:400 */
			qdec {
				compatible = "st,stm32-qdec";    /* in zephyr/dts/arm/st/f4/stm32f4.dtsi:401 */
				st,input-filter-level = < 0x0 >; /* in zephyr/dts/arm/st/f4/stm32f4.dtsi:402 */
				status = "disabled";             /* in zephyr/dts/arm/st/f4/stm32f4.dtsi:403 */
			};
		};

		/* node '/soc/timers@40000000' defined in zephyr/dts/arm/st/f4/stm32f4.dtsi:407 */
		timers2: timers@40000000 {
			compatible = "st,stm32-timers"; /* in zephyr/dts/arm/st/f4/stm32f4.dtsi:408 */
			reg = < 0x40000000 0x400 >;     /* in zephyr/dts/arm/st/f4/stm32f4.dtsi:409 */
			clocks = < &rcc 0x40 0x1 >,
			         < &rcc 0x15 0xff >;    /* in zephyr/dts/arm/st/f4/stm32f4.dtsi:410 */
			resets = < &rctl 0x400 >;       /* in zephyr/dts/arm/st/f4/stm32f4.dtsi:412 */
			interrupts = < 0x1c 0x0 >;      /* in zephyr/dts/arm/st/f4/stm32f4.dtsi:413 */
			interrupt-names = "global";     /* in zephyr/dts/arm/st/f4/stm32f4.dtsi:414 */
			status = "okay";                /* in rbc_main_zephyr/boards/rbc_mainboard/rbc_mainboard.dts:332 */
			st,prescaler = < 0x0 >;         /* in rbc_main_zephyr/boards/rbc_mainboard/rbc_mainboard.dts:333 */

			/* node '/soc/timers@40000000/pwm' defined in zephyr/dts/arm/st/f4/stm32f4.dtsi:418 */
			pwm {
				compatible = "st,stm32-pwm"; /* in zephyr/dts/arm/st/f4/stm32f4.dtsi:419 */
				status = "disabled";         /* in zephyr/dts/arm/st/f4/stm32f4.dtsi:420 */
				#pwm-cells = < 0x3 >;        /* in zephyr/dts/arm/st/f4/stm32f4.dtsi:421 */
			};

			/* node '/soc/timers@40000000/counter' defined in zephyr/dts/arm/st/f4/stm32f4.dtsi:424 */
			counter {
				compatible = "st,stm32-counter"; /* in zephyr/dts/arm/st/f4/stm32f4.dtsi:425 */
				status = "disabled";             /* in zephyr/dts/arm/st/f4/stm32f4.dtsi:426 */
			};

			/* node '/soc/timers@40000000/qdec' defined in zephyr/dts/arm/st/f4/stm32f4.dtsi:429 */
			qdec2: qdec {
				compatible = "st,stm32-qdec";                 /* in rbc_main_zephyr/boards/rbc_mainboard/rbc_mainboard.dts:336 */
				status = "okay";                              /* in rbc_main_zephyr/boards/rbc_mainboard/rbc_mainboard.dts:337 */
				pinctrl-0 = < &tim2_ch1_pa15 &tim2_ch2_pb3 >; /* in rbc_main_zephyr/boards/rbc_mainboard/rbc_mainboard.dts:338 */
				pinctrl-names = "default";                    /* in rbc_main_zephyr/boards/rbc_mainboard/rbc_mainboard.dts:339 */
				st,encoder-mode = < 0x3 >;                    /* in rbc_main_zephyr/boards/rbc_mainboard/rbc_mainboard.dts:340 */
				st,input-filter-level = < 0x0 >;              /* in rbc_main_zephyr/boards/rbc_mainboard/rbc_mainboard.dts:341 */
				st,counts-per-revolution = < 0xffff >;        /* in rbc_main_zephyr/boards/rbc_mainboard/rbc_mainboard.dts:342 */
			};
		};

		/* node '/soc/timers@40000400' defined in zephyr/dts/arm/st/f4/stm32f4.dtsi:436 */
		timers3: timers@40000400 {
			compatible = "st,stm32-timers"; /* in zephyr/dts/arm/st/f4/stm32f4.dtsi:437 */
			reg = < 0x40000400 0x400 >;     /* in zephyr/dts/arm/st/f4/stm32f4.dtsi:438 */
			clocks = < &rcc 0x40 0x2 >,
			         < &rcc 0x15 0xff >;    /* in zephyr/dts/arm/st/f4/stm32f4.dtsi:439 */
			resets = < &rctl 0x401 >;       /* in zephyr/dts/arm/st/f4/stm32f4.dtsi:441 */
			interrupts = < 0x1d 0x0 >;      /* in zephyr/dts/arm/st/f4/stm32f4.dtsi:442 */
			interrupt-names = "global";     /* in zephyr/dts/arm/st/f4/stm32f4.dtsi:443 */
			status = "okay";                /* in rbc_main_zephyr/boards/rbc_mainboard/rbc_mainboard.dts:347 */
			st,prescaler = < 0x0 >;         /* in rbc_main_zephyr/boards/rbc_mainboard/rbc_mainboard.dts:348 */

			/* node '/soc/timers@40000400/pwm' defined in zephyr/dts/arm/st/f4/stm32f4.dtsi:447 */
			pwm {
				compatible = "st,stm32-pwm"; /* in zephyr/dts/arm/st/f4/stm32f4.dtsi:448 */
				status = "disabled";         /* in zephyr/dts/arm/st/f4/stm32f4.dtsi:449 */
				#pwm-cells = < 0x3 >;        /* in zephyr/dts/arm/st/f4/stm32f4.dtsi:450 */
			};

			/* node '/soc/timers@40000400/counter' defined in zephyr/dts/arm/st/f4/stm32f4.dtsi:453 */
			counter {
				compatible = "st,stm32-counter"; /* in zephyr/dts/arm/st/f4/stm32f4.dtsi:454 */
				status = "disabled";             /* in zephyr/dts/arm/st/f4/stm32f4.dtsi:455 */
			};

			/* node '/soc/timers@40000400/qdec' defined in zephyr/dts/arm/st/f4/stm32f4.dtsi:458 */
			qdec3: qdec {
				compatible = "st,stm32-qdec";                /* in rbc_main_zephyr/boards/rbc_mainboard/rbc_mainboard.dts:351 */
				status = "okay";                             /* in rbc_main_zephyr/boards/rbc_mainboard/rbc_mainboard.dts:352 */
				pinctrl-0 = < &tim3_ch1_pc6 &tim3_ch2_pc7 >; /* in rbc_main_zephyr/boards/rbc_mainboard/rbc_mainboard.dts:353 */
				pinctrl-names = "default";                   /* in rbc_main_zephyr/boards/rbc_mainboard/rbc_mainboard.dts:354 */
				st,encoder-mode = < 0x3 >;                   /* in rbc_main_zephyr/boards/rbc_mainboard/rbc_mainboard.dts:355 */
				st,input-filter-level = < 0x0 >;             /* in rbc_main_zephyr/boards/rbc_mainboard/rbc_mainboard.dts:356 */
				st,counts-per-revolution = < 0xffff >;       /* in rbc_main_zephyr/boards/rbc_mainboard/rbc_mainboard.dts:357 */
			};
		};

		/* node '/soc/timers@40000800' defined in zephyr/dts/arm/st/f4/stm32f4.dtsi:465 */
		timers4: timers@40000800 {
			compatible = "st,stm32-timers"; /* in zephyr/dts/arm/st/f4/stm32f4.dtsi:466 */
			reg = < 0x40000800 0x400 >;     /* in zephyr/dts/arm/st/f4/stm32f4.dtsi:467 */
			clocks = < &rcc 0x40 0x4 >,
			         < &rcc 0x15 0xff >;    /* in zephyr/dts/arm/st/f4/stm32f4.dtsi:468 */
			resets = < &rctl 0x402 >;       /* in zephyr/dts/arm/st/f4/stm32f4.dtsi:470 */
			interrupts = < 0x1e 0x0 >;      /* in zephyr/dts/arm/st/f4/stm32f4.dtsi:471 */
			interrupt-names = "global";     /* in zephyr/dts/arm/st/f4/stm32f4.dtsi:472 */
			status = "okay";                /* in rbc_main_zephyr/boards/rbc_mainboard/rbc_mainboard.dts:362 */
			st,prescaler = < 0x0 >;         /* in rbc_main_zephyr/boards/rbc_mainboard/rbc_mainboard.dts:363 */

			/* node '/soc/timers@40000800/pwm' defined in zephyr/dts/arm/st/f4/stm32f4.dtsi:476 */
			pwm {
				compatible = "st,stm32-pwm"; /* in zephyr/dts/arm/st/f4/stm32f4.dtsi:477 */
				status = "disabled";         /* in zephyr/dts/arm/st/f4/stm32f4.dtsi:478 */
				#pwm-cells = < 0x3 >;        /* in zephyr/dts/arm/st/f4/stm32f4.dtsi:479 */
			};

			/* node '/soc/timers@40000800/counter' defined in zephyr/dts/arm/st/f4/stm32f4.dtsi:482 */
			counter {
				compatible = "st,stm32-counter"; /* in zephyr/dts/arm/st/f4/stm32f4.dtsi:483 */
				status = "disabled";             /* in zephyr/dts/arm/st/f4/stm32f4.dtsi:484 */
			};

			/* node '/soc/timers@40000800/qdec' defined in zephyr/dts/arm/st/f4/stm32f4.dtsi:487 */
			qdec4: qdec {
				compatible = "st,stm32-qdec";                  /* in rbc_main_zephyr/boards/rbc_mainboard/rbc_mainboard.dts:366 */
				status = "okay";                               /* in rbc_main_zephyr/boards/rbc_mainboard/rbc_mainboard.dts:367 */
				pinctrl-0 = < &tim4_ch1_pd12 &tim4_ch2_pd13 >; /* in rbc_main_zephyr/boards/rbc_mainboard/rbc_mainboard.dts:368 */
				pinctrl-names = "default";                     /* in rbc_main_zephyr/boards/rbc_mainboard/rbc_mainboard.dts:369 */
				st,encoder-mode = < 0x3 >;                     /* in rbc_main_zephyr/boards/rbc_mainboard/rbc_mainboard.dts:370 */
				st,input-filter-level = < 0x0 >;               /* in rbc_main_zephyr/boards/rbc_mainboard/rbc_mainboard.dts:371 */
				st,counts-per-revolution = < 0xffff >;         /* in rbc_main_zephyr/boards/rbc_mainboard/rbc_mainboard.dts:372 */
			};
		};

		/* node '/soc/timers@40000c00' defined in zephyr/dts/arm/st/f4/stm32f4.dtsi:494 */
		timers5: timers@40000c00 {
			compatible = "st,stm32-timers"; /* in zephyr/dts/arm/st/f4/stm32f4.dtsi:495 */
			reg = < 0x40000c00 0x400 >;     /* in zephyr/dts/arm/st/f4/stm32f4.dtsi:496 */
			clocks = < &rcc 0x40 0x8 >,
			         < &rcc 0x15 0xff >;    /* in zephyr/dts/arm/st/f4/stm32f4.dtsi:497 */
			resets = < &rctl 0x403 >;       /* in zephyr/dts/arm/st/f4/stm32f4.dtsi:499 */
			interrupts = < 0x32 0x0 >;      /* in zephyr/dts/arm/st/f4/stm32f4.dtsi:500 */
			interrupt-names = "global";     /* in zephyr/dts/arm/st/f4/stm32f4.dtsi:501 */
			st,prescaler = < 0x0 >;         /* in zephyr/dts/arm/st/f4/stm32f4.dtsi:502 */
			status = "disabled";            /* in zephyr/dts/arm/st/f4/stm32f4.dtsi:503 */

			/* node '/soc/timers@40000c00/pwm' defined in zephyr/dts/arm/st/f4/stm32f4.dtsi:505 */
			pwm {
				compatible = "st,stm32-pwm"; /* in zephyr/dts/arm/st/f4/stm32f4.dtsi:506 */
				status = "disabled";         /* in zephyr/dts/arm/st/f4/stm32f4.dtsi:507 */
				#pwm-cells = < 0x3 >;        /* in zephyr/dts/arm/st/f4/stm32f4.dtsi:508 */
			};

			/* node '/soc/timers@40000c00/counter' defined in zephyr/dts/arm/st/f4/stm32f4.dtsi:511 */
			counter {
				compatible = "st,stm32-counter"; /* in zephyr/dts/arm/st/f4/stm32f4.dtsi:512 */
				status = "disabled";             /* in zephyr/dts/arm/st/f4/stm32f4.dtsi:513 */
			};

			/* node '/soc/timers@40000c00/qdec' defined in zephyr/dts/arm/st/f4/stm32f4.dtsi:516 */
			qdec {
				compatible = "st,stm32-qdec";    /* in zephyr/dts/arm/st/f4/stm32f4.dtsi:517 */
				st,input-filter-level = < 0x0 >; /* in zephyr/dts/arm/st/f4/stm32f4.dtsi:518 */
				status = "disabled";             /* in zephyr/dts/arm/st/f4/stm32f4.dtsi:519 */
			};
		};

		/* node '/soc/timers@40014000' defined in zephyr/dts/arm/st/f4/stm32f4.dtsi:523 */
		timers9: timers@40014000 {
			compatible = "st,stm32-timers"; /* in zephyr/dts/arm/st/f4/stm32f4.dtsi:524 */
			reg = < 0x40014000 0x400 >;     /* in zephyr/dts/arm/st/f4/stm32f4.dtsi:525 */
			clocks = < &rcc 0x44 0x10000 >,
			         < &rcc 0x16 0xff >;    /* in zephyr/dts/arm/st/f4/stm32f4.dtsi:526 */
			resets = < &rctl 0x490 >;       /* in zephyr/dts/arm/st/f4/stm32f4.dtsi:528 */
			interrupts = < 0x18 0x0 >;      /* in zephyr/dts/arm/st/f4/stm32f4.dtsi:529 */
			interrupt-names = "global";     /* in zephyr/dts/arm/st/f4/stm32f4.dtsi:530 */
			st,prescaler = < 0x0 >;         /* in zephyr/dts/arm/st/f4/stm32f4.dtsi:531 */
			status = "okay";                /* in rbc_main_zephyr/boards/rbc_mainboard/rbc_mainboard.dts:414 */

			/* node '/soc/timers@40014000/pwm' defined in zephyr/dts/arm/st/f4/stm32f4.dtsi:534 */
			pwm9: pwm {
				compatible = "st,stm32-pwm";   /* in rbc_main_zephyr/boards/rbc_mainboard/rbc_mainboard.dts:417 */
				status = "okay";               /* in rbc_main_zephyr/boards/rbc_mainboard/rbc_mainboard.dts:418 */
				pinctrl-0 = < &tim9_ch2_pe6 >; /* in rbc_main_zephyr/boards/rbc_mainboard/rbc_mainboard.dts:419 */
				pinctrl-names = "default";     /* in rbc_main_zephyr/boards/rbc_mainboard/rbc_mainboard.dts:420 */
				#pwm-cells = < 0x3 >;          /* in rbc_main_zephyr/boards/rbc_mainboard/rbc_mainboard.dts:421 */
			};

			/* node '/soc/timers@40014000/counter' defined in zephyr/dts/arm/st/f4/stm32f4.dtsi:540 */
			counter {
				compatible = "st,stm32-counter"; /* in zephyr/dts/arm/st/f4/stm32f4.dtsi:541 */
				status = "disabled";             /* in zephyr/dts/arm/st/f4/stm32f4.dtsi:542 */
			};
		};

		/* node '/soc/timers@40014400' defined in zephyr/dts/arm/st/f4/stm32f4.dtsi:546 */
		timers10: timers@40014400 {
			compatible = "st,stm32-timers"; /* in zephyr/dts/arm/st/f4/stm32f4.dtsi:547 */
			reg = < 0x40014400 0x400 >;     /* in zephyr/dts/arm/st/f4/stm32f4.dtsi:548 */
			clocks = < &rcc 0x44 0x20000 >,
			         < &rcc 0x16 0xff >;    /* in zephyr/dts/arm/st/f4/stm32f4.dtsi:549 */
			resets = < &rctl 0x491 >;       /* in zephyr/dts/arm/st/f4/stm32f4.dtsi:551 */
			interrupts = < 0x19 0x0 >;      /* in zephyr/dts/arm/st/f4/stm32f4.dtsi:552 */
			interrupt-names = "global";     /* in zephyr/dts/arm/st/f4/stm32f4.dtsi:553 */
			st,prescaler = < 0x0 >;         /* in zephyr/dts/arm/st/f4/stm32f4.dtsi:554 */
			status = "disabled";            /* in zephyr/dts/arm/st/f4/stm32f4.dtsi:555 */

			/* node '/soc/timers@40014400/pwm' defined in zephyr/dts/arm/st/f4/stm32f4.dtsi:557 */
			pwm {
				compatible = "st,stm32-pwm"; /* in zephyr/dts/arm/st/f4/stm32f4.dtsi:558 */
				status = "disabled";         /* in zephyr/dts/arm/st/f4/stm32f4.dtsi:559 */
				#pwm-cells = < 0x3 >;        /* in zephyr/dts/arm/st/f4/stm32f4.dtsi:560 */
			};

			/* node '/soc/timers@40014400/counter' defined in zephyr/dts/arm/st/f4/stm32f4.dtsi:563 */
			counter {
				compatible = "st,stm32-counter"; /* in zephyr/dts/arm/st/f4/stm32f4.dtsi:564 */
				status = "disabled";             /* in zephyr/dts/arm/st/f4/stm32f4.dtsi:565 */
			};
		};

		/* node '/soc/timers@40014800' defined in zephyr/dts/arm/st/f4/stm32f4.dtsi:569 */
		timers11: timers@40014800 {
			compatible = "st,stm32-timers"; /* in zephyr/dts/arm/st/f4/stm32f4.dtsi:570 */
			reg = < 0x40014800 0x400 >;     /* in zephyr/dts/arm/st/f4/stm32f4.dtsi:571 */
			clocks = < &rcc 0x44 0x40000 >,
			         < &rcc 0x16 0xff >;    /* in zephyr/dts/arm/st/f4/stm32f4.dtsi:572 */
			resets = < &rctl 0x492 >;       /* in zephyr/dts/arm/st/f4/stm32f4.dtsi:574 */
			interrupts = < 0x1a 0x0 >;      /* in zephyr/dts/arm/st/f4/stm32f4.dtsi:575 */
			interrupt-names = "global";     /* in zephyr/dts/arm/st/f4/stm32f4.dtsi:576 */
			st,prescaler = < 0x0 >;         /* in zephyr/dts/arm/st/f4/stm32f4.dtsi:577 */
			status = "disabled";            /* in zephyr/dts/arm/st/f4/stm32f4.dtsi:578 */

			/* node '/soc/timers@40014800/pwm' defined in zephyr/dts/arm/st/f4/stm32f4.dtsi:580 */
			pwm {
				compatible = "st,stm32-pwm"; /* in zephyr/dts/arm/st/f4/stm32f4.dtsi:581 */
				status = "disabled";         /* in zephyr/dts/arm/st/f4/stm32f4.dtsi:582 */
				#pwm-cells = < 0x3 >;        /* in zephyr/dts/arm/st/f4/stm32f4.dtsi:583 */
			};

			/* node '/soc/timers@40014800/counter' defined in zephyr/dts/arm/st/f4/stm32f4.dtsi:586 */
			counter {
				compatible = "st,stm32-counter"; /* in zephyr/dts/arm/st/f4/stm32f4.dtsi:587 */
				status = "disabled";             /* in zephyr/dts/arm/st/f4/stm32f4.dtsi:588 */
			};
		};

		/* node '/soc/rtc@40002800' defined in zephyr/dts/arm/st/f4/stm32f4.dtsi:592 */
		rtc: rtc@40002800 {
			compatible = "st,stm32-rtc";       /* in zephyr/dts/arm/st/f4/stm32f4.dtsi:593 */
			reg = < 0x40002800 0x400 >;        /* in zephyr/dts/arm/st/f4/stm32f4.dtsi:594 */
			interrupts = < 0x29 0x0 >;         /* in zephyr/dts/arm/st/f4/stm32f4.dtsi:595 */
			clocks = < &rcc 0x40 0x10000000 >; /* in zephyr/dts/arm/st/f4/stm32f4.dtsi:596 */
			prescaler = < 0x8000 >;            /* in zephyr/dts/arm/st/f4/stm32f4.dtsi:597 */
			alarms-count = < 0x2 >;            /* in zephyr/dts/arm/st/f4/stm32f4.dtsi:598 */
			alrm-exti-line = < 0x11 >;         /* in zephyr/dts/arm/st/f4/stm32f4.dtsi:599 */
			status = "disabled";               /* in zephyr/dts/arm/st/f4/stm32f4.dtsi:600 */

			/* node '/soc/rtc@40002800/backup_regs' defined in zephyr/dts/arm/st/f4/stm32f4.dtsi:602 */
			bbram: backup_regs {
				compatible = "st,stm32-bbram"; /* in zephyr/dts/arm/st/f4/stm32f4.dtsi:603 */
				st,backup-regs = < 0x14 >;     /* in zephyr/dts/arm/st/f4/stm32f4.dtsi:604 */
				status = "disabled";           /* in zephyr/dts/arm/st/f4/stm32f4.dtsi:605 */
			};
		};

		/* node '/soc/adc@40012000' defined in zephyr/dts/arm/st/f4/stm32f4.dtsi:609 */
		adc1: adc@40012000 {
			compatible = "st,stm32f4-adc",
			             "st,stm32-adc";                                 /* in zephyr/dts/arm/st/f4/stm32f4.dtsi:610 */
			reg = < 0x40012000 0x400 >;                                  /* in zephyr/dts/arm/st/f4/stm32f4.dtsi:611 */
			clocks = < &rcc 0x44 0x100 >;                                /* in zephyr/dts/arm/st/f4/stm32f4.dtsi:612 */
			clock-names = "adcx";                                        /* in zephyr/dts/arm/st/f4/stm32f4.dtsi:613 */
			interrupts = < 0x12 0x0 >;                                   /* in zephyr/dts/arm/st/f4/stm32f4.dtsi:614 */
			#io-channel-cells = < 0x1 >;                                 /* in zephyr/dts/arm/st/f4/stm32f4.dtsi:615 */
			st,adc-resolutions = < 0xc 0xa 0x8 0x6 >;                    /* in zephyr/dts/arm/st/f4/stm32f4.dtsi:616 */
			sampling-times = < 0x3 0xf 0x1c 0x38 0x54 0x70 0x90 0x1e0 >; /* in zephyr/dts/arm/st/f4/stm32f4.dtsi:617 */
			st,adc-clock-source = "SYNC";                                /* in zephyr/dts/arm/st/f4/stm32f4.dtsi:618 */
			st,adc-sequencer = "programmable";                           /* in zephyr/dts/arm/st/f4/stm32f4.dtsi:619 */
			st,adc-oversampler = "none";                                 /* in zephyr/dts/arm/st/f4/stm32f4.dtsi:620 */
			st,adc-internal-regulator = "none";                          /* in zephyr/dts/arm/st/f4/stm32f4.dtsi:621 */
			st,adc-has-injected-support;                                 /* in zephyr/dts/arm/st/f4/stm32f4.dtsi:622 */
			pinctrl-0 = < &adc1_in0_pa0 >;                               /* in rbc_main_zephyr/boards/rbc_mainboard/rbc_mainboard.dts:319 */
			pinctrl-names = "default";                                   /* in rbc_main_zephyr/boards/rbc_mainboard/rbc_mainboard.dts:320 */
			st,adc-prescaler = < 0x2 >;                                  /* in rbc_main_zephyr/boards/rbc_mainboard/rbc_mainboard.dts:321 */
			status = "okay";                                             /* in rbc_main_zephyr/boards/rbc_mainboard/rbc_mainboard.dts:322 */
			phandle = < 0x28 >;                                          /* in zephyr/dts/arm/st/f4/stm32f4.dtsi:679 */
		};

		/* node '/soc/dma@40026000' defined in zephyr/dts/arm/st/f4/stm32f4.dtsi:626 */
		dma1: dma@40026000 {
			compatible = "st,stm32-dma-v1";                                                      /* in zephyr/dts/arm/st/f4/stm32f4.dtsi:627 */
			#dma-cells = < 0x4 >;                                                                /* in zephyr/dts/arm/st/f4/stm32f4.dtsi:628 */
			reg = < 0x40026000 0x400 >;                                                          /* in zephyr/dts/arm/st/f4/stm32f4.dtsi:629 */
			interrupts = < 0xb 0x0 0xc 0x0 0xd 0x0 0xe 0x0 0xf 0x0 0x10 0x0 0x11 0x0 0x2f 0x0 >; /* in zephyr/dts/arm/st/f4/stm32f4.dtsi:630 */
			clocks = < &rcc 0x30 0x200000 >;                                                     /* in zephyr/dts/arm/st/f4/stm32f4.dtsi:631 */
			status = "okay";                                                                     /* in rbc_main_zephyr/boards/rbc_mainboard/rbc_mainboard.dts:459 */
			phandle = < 0x1b >;                                                                  /* in zephyr/dts/arm/st/f4/stm32f401.dtsi:61 */
		};

		/* node '/soc/dma@40026400' defined in zephyr/dts/arm/st/f4/stm32f4.dtsi:635 */
		dma2: dma@40026400 {
			compatible = "st,stm32-dma-v1";                                                           /* in zephyr/dts/arm/st/f4/stm32f4.dtsi:636 */
			#dma-cells = < 0x4 >;                                                                     /* in zephyr/dts/arm/st/f4/stm32f4.dtsi:637 */
			reg = < 0x40026400 0x400 >;                                                               /* in zephyr/dts/arm/st/f4/stm32f4.dtsi:638 */
			interrupts = < 0x38 0x0 0x39 0x0 0x3a 0x0 0x3b 0x0 0x3c 0x0 0x44 0x0 0x45 0x0 0x46 0x0 >; /* in zephyr/dts/arm/st/f4/stm32f4.dtsi:639 */
			clocks = < &rcc 0x30 0x400000 >;                                                          /* in zephyr/dts/arm/st/f4/stm32f4.dtsi:640 */
			st,mem2mem;                                                                               /* in zephyr/dts/arm/st/f4/stm32f4.dtsi:641 */
			status = "okay";                                                                          /* in rbc_main_zephyr/boards/rbc_mainboard/rbc_mainboard.dts:463 */
		};

		/* node '/soc/sdmmc@40012c00' defined in zephyr/dts/arm/st/f4/stm32f4.dtsi:645 */
		sdmmc1: sdmmc@40012c00 {
			compatible = "st,stm32-sdmmc"; /* in zephyr/dts/arm/st/f4/stm32f4.dtsi:646 */
			reg = < 0x40012c00 0x400 >;    /* in zephyr/dts/arm/st/f4/stm32f4.dtsi:647 */
			clocks = < &rcc 0x44 0x800 >,
			         < &rcc 0x7 0xff >;    /* in zephyr/dts/arm/st/f4/stm32f4.dtsi:648 */
			resets = < &rctl 0x48b >;      /* in zephyr/dts/arm/st/f4/stm32f4.dtsi:650 */
			interrupts = < 0x31 0x0 >;     /* in zephyr/dts/arm/st/f4/stm32f4.dtsi:651 */
			status = "disabled";           /* in zephyr/dts/arm/st/f4/stm32f4.dtsi:652 */
		};

		/* node '/soc/spi@40003800' defined in zephyr/dts/arm/st/f4/stm32f401.dtsi:21 */
		spi2: spi@40003800 {
			compatible = "st,stm32-spi";            /* in zephyr/dts/arm/st/f4/stm32f401.dtsi:22 */
			#address-cells = < 0x1 >;               /* in zephyr/dts/arm/st/f4/stm32f401.dtsi:23 */
			#size-cells = < 0x0 >;                  /* in zephyr/dts/arm/st/f4/stm32f401.dtsi:24 */
			reg = < 0x40003800 0x400 >;             /* in zephyr/dts/arm/st/f4/stm32f401.dtsi:25 */
			clocks = < &rcc 0x40 0x4000 >;          /* in zephyr/dts/arm/st/f4/stm32f401.dtsi:26 */
			interrupts = < 0x24 0x0 >;              /* in zephyr/dts/arm/st/f4/stm32f401.dtsi:27 */
			st,spi-data-width = "limited-8-16-bit"; /* in zephyr/dts/arm/st/f4/stm32f401.dtsi:28 */
			status = "disabled";                    /* in zephyr/dts/arm/st/f4/stm32f401.dtsi:29 */
		};

		/* node '/soc/spi@40003c00' defined in zephyr/dts/arm/st/f4/stm32f401.dtsi:32 */
		spi3: spi@40003c00 {
			compatible = "st,stm32-spi";            /* in zephyr/dts/arm/st/f4/stm32f401.dtsi:33 */
			#address-cells = < 0x1 >;               /* in zephyr/dts/arm/st/f4/stm32f401.dtsi:34 */
			#size-cells = < 0x0 >;                  /* in zephyr/dts/arm/st/f4/stm32f401.dtsi:35 */
			reg = < 0x40003c00 0x400 >;             /* in zephyr/dts/arm/st/f4/stm32f401.dtsi:36 */
			clocks = < &rcc 0x40 0x8000 >;          /* in zephyr/dts/arm/st/f4/stm32f401.dtsi:37 */
			interrupts = < 0x33 0x0 >;              /* in zephyr/dts/arm/st/f4/stm32f401.dtsi:38 */
			st,spi-data-width = "limited-8-16-bit"; /* in zephyr/dts/arm/st/f4/stm32f401.dtsi:39 */
			status = "disabled";                    /* in zephyr/dts/arm/st/f4/stm32f401.dtsi:40 */
		};

		/* node '/soc/spi@40013400' defined in zephyr/dts/arm/st/f4/stm32f401.dtsi:43 */
		spi4: spi@40013400 {
			compatible = "st,stm32-spi";            /* in zephyr/dts/arm/st/f4/stm32f401.dtsi:44 */
			#address-cells = < 0x1 >;               /* in zephyr/dts/arm/st/f4/stm32f401.dtsi:45 */
			#size-cells = < 0x0 >;                  /* in zephyr/dts/arm/st/f4/stm32f401.dtsi:46 */
			reg = < 0x40013400 0x400 >;             /* in zephyr/dts/arm/st/f4/stm32f401.dtsi:47 */
			clocks = < &rcc 0x44 0x2000 >;          /* in zephyr/dts/arm/st/f4/stm32f401.dtsi:48 */
			interrupts = < 0x54 0x0 >;              /* in zephyr/dts/arm/st/f4/stm32f401.dtsi:49 */
			st,spi-data-width = "limited-8-16-bit"; /* in zephyr/dts/arm/st/f4/stm32f401.dtsi:50 */
			status = "disabled";                    /* in zephyr/dts/arm/st/f4/stm32f401.dtsi:51 */
		};

		/* node '/soc/i2s@40003800' defined in zephyr/dts/arm/st/f4/stm32f401.dtsi:54 */
		i2s2: i2s@40003800 {
			compatible = "st,stm32-i2s";        /* in zephyr/dts/arm/st/f4/stm32f401.dtsi:55 */
			#address-cells = < 0x1 >;           /* in zephyr/dts/arm/st/f4/stm32f401.dtsi:56 */
			#size-cells = < 0x0 >;              /* in zephyr/dts/arm/st/f4/stm32f401.dtsi:57 */
			reg = < 0x40003800 0x400 >;         /* in zephyr/dts/arm/st/f4/stm32f401.dtsi:58 */
			clocks = < &rcc 0x40 0x4000 >;      /* in zephyr/dts/arm/st/f4/stm32f401.dtsi:59 */
			interrupts = < 0x24 0x0 >;          /* in zephyr/dts/arm/st/f4/stm32f401.dtsi:60 */
			dmas = < &dma1 0x4 0x0 0x400 0x3 >,
			       < &dma1 0x3 0x0 0x400 0x3 >; /* in zephyr/dts/arm/st/f4/stm32f401.dtsi:61 */
			dma-names = "tx",
			            "rx";                   /* in zephyr/dts/arm/st/f4/stm32f401.dtsi:63 */
			status = "disabled";                /* in zephyr/dts/arm/st/f4/stm32f401.dtsi:64 */
		};

		/* node '/soc/i2s@40003c00' defined in zephyr/dts/arm/st/f4/stm32f401.dtsi:67 */
		i2s3: i2s@40003c00 {
			compatible = "st,stm32-i2s";        /* in zephyr/dts/arm/st/f4/stm32f401.dtsi:68 */
			#address-cells = < 0x1 >;           /* in zephyr/dts/arm/st/f4/stm32f401.dtsi:69 */
			#size-cells = < 0x0 >;              /* in zephyr/dts/arm/st/f4/stm32f401.dtsi:70 */
			reg = < 0x40003c00 0x400 >;         /* in zephyr/dts/arm/st/f4/stm32f401.dtsi:71 */
			clocks = < &rcc 0x40 0x8000 >;      /* in zephyr/dts/arm/st/f4/stm32f401.dtsi:72 */
			interrupts = < 0x33 0x0 >;          /* in zephyr/dts/arm/st/f4/stm32f401.dtsi:73 */
			dmas = < &dma1 0x5 0x0 0x400 0x3 >,
			       < &dma1 0x0 0x0 0x400 0x3 >; /* in zephyr/dts/arm/st/f4/stm32f401.dtsi:74 */
			dma-names = "tx",
			            "rx";                   /* in zephyr/dts/arm/st/f4/stm32f401.dtsi:76 */
			status = "disabled";                /* in zephyr/dts/arm/st/f4/stm32f401.dtsi:77 */
		};

		/* node '/soc/serial@40004800' defined in zephyr/dts/arm/st/f4/stm32f405.dtsi:51 */
		usart3: serial@40004800 {
			compatible = "st,stm32-usart",
			             "st,stm32-uart";                  /* in zephyr/dts/arm/st/f4/stm32f405.dtsi:52 */
			reg = < 0x40004800 0x400 >;                    /* in zephyr/dts/arm/st/f4/stm32f405.dtsi:53 */
			clocks = < &rcc 0x40 0x40000 >;                /* in zephyr/dts/arm/st/f4/stm32f405.dtsi:54 */
			resets = < &rctl 0x412 >;                      /* in zephyr/dts/arm/st/f4/stm32f405.dtsi:55 */
			interrupts = < 0x27 0x0 >;                     /* in zephyr/dts/arm/st/f4/stm32f405.dtsi:56 */
			pinctrl-0 = < &usart3_tx_pd8 &usart3_rx_pd9 >; /* in rbc_main_zephyr/boards/rbc_mainboard/rbc_mainboard.dts:257 */
			pinctrl-names = "default";                     /* in rbc_main_zephyr/boards/rbc_mainboard/rbc_mainboard.dts:258 */
			current-speed = < 0x1c200 >;                   /* in rbc_main_zephyr/boards/rbc_mainboard/rbc_mainboard.dts:259 */
			status = "okay";                               /* in rbc_main_zephyr/boards/rbc_mainboard/rbc_mainboard.dts:260 */
		};

		/* node '/soc/serial@40004c00' defined in zephyr/dts/arm/st/f4/stm32f405.dtsi:60 */
		uart4: serial@40004c00 {
			compatible = "st,stm32-uart";   /* in zephyr/dts/arm/st/f4/stm32f405.dtsi:61 */
			reg = < 0x40004c00 0x400 >;     /* in zephyr/dts/arm/st/f4/stm32f405.dtsi:62 */
			clocks = < &rcc 0x40 0x80000 >; /* in zephyr/dts/arm/st/f4/stm32f405.dtsi:63 */
			resets = < &rctl 0x413 >;       /* in zephyr/dts/arm/st/f4/stm32f405.dtsi:64 */
			interrupts = < 0x34 0x0 >;      /* in zephyr/dts/arm/st/f4/stm32f405.dtsi:65 */
			status = "disabled";            /* in zephyr/dts/arm/st/f4/stm32f405.dtsi:66 */
		};

		/* node '/soc/serial@40005000' defined in zephyr/dts/arm/st/f4/stm32f405.dtsi:69 */
		uart5: serial@40005000 {
			compatible = "st,stm32-uart";    /* in zephyr/dts/arm/st/f4/stm32f405.dtsi:70 */
			reg = < 0x40005000 0x400 >;      /* in zephyr/dts/arm/st/f4/stm32f405.dtsi:71 */
			clocks = < &rcc 0x40 0x100000 >; /* in zephyr/dts/arm/st/f4/stm32f405.dtsi:72 */
			resets = < &rctl 0x414 >;        /* in zephyr/dts/arm/st/f4/stm32f405.dtsi:73 */
			interrupts = < 0x35 0x0 >;       /* in zephyr/dts/arm/st/f4/stm32f405.dtsi:74 */
			status = "disabled";             /* in zephyr/dts/arm/st/f4/stm32f405.dtsi:75 */
		};

		/* node '/soc/timers@40001000' defined in zephyr/dts/arm/st/f4/stm32f405.dtsi:78 */
		timers6: timers@40001000 {
			compatible = "st,stm32-timers"; /* in zephyr/dts/arm/st/f4/stm32f405.dtsi:79 */
			reg = < 0x40001000 0x400 >;     /* in zephyr/dts/arm/st/f4/stm32f405.dtsi:80 */
			clocks = < &rcc 0x40 0x10 >,
			         < &rcc 0x15 0xff >;    /* in zephyr/dts/arm/st/f4/stm32f405.dtsi:81 */
			resets = < &rctl 0x404 >;       /* in zephyr/dts/arm/st/f4/stm32f405.dtsi:83 */
			interrupts = < 0x36 0x0 >;      /* in zephyr/dts/arm/st/f4/stm32f405.dtsi:84 */
			interrupt-names = "global";     /* in zephyr/dts/arm/st/f4/stm32f405.dtsi:85 */
			st,prescaler = < 0x0 >;         /* in zephyr/dts/arm/st/f4/stm32f405.dtsi:86 */
			status = "disabled";            /* in zephyr/dts/arm/st/f4/stm32f405.dtsi:87 */

			/* node '/soc/timers@40001000/counter' defined in zephyr/dts/arm/st/f4/stm32f405.dtsi:89 */
			counter {
				compatible = "st,stm32-counter"; /* in zephyr/dts/arm/st/f4/stm32f405.dtsi:90 */
				status = "disabled";             /* in zephyr/dts/arm/st/f4/stm32f405.dtsi:91 */
			};
		};

		/* node '/soc/timers@40001400' defined in zephyr/dts/arm/st/f4/stm32f405.dtsi:95 */
		timers7: timers@40001400 {
			compatible = "st,stm32-timers"; /* in zephyr/dts/arm/st/f4/stm32f405.dtsi:96 */
			reg = < 0x40001400 0x400 >;     /* in zephyr/dts/arm/st/f4/stm32f405.dtsi:97 */
			clocks = < &rcc 0x40 0x20 >,
			         < &rcc 0x15 0xff >;    /* in zephyr/dts/arm/st/f4/stm32f405.dtsi:98 */
			resets = < &rctl 0x405 >;       /* in zephyr/dts/arm/st/f4/stm32f405.dtsi:100 */
			interrupts = < 0x37 0x0 >;      /* in zephyr/dts/arm/st/f4/stm32f405.dtsi:101 */
			interrupt-names = "global";     /* in zephyr/dts/arm/st/f4/stm32f405.dtsi:102 */
			st,prescaler = < 0x0 >;         /* in zephyr/dts/arm/st/f4/stm32f405.dtsi:103 */
			status = "disabled";            /* in zephyr/dts/arm/st/f4/stm32f405.dtsi:104 */

			/* node '/soc/timers@40001400/counter' defined in zephyr/dts/arm/st/f4/stm32f405.dtsi:106 */
			counter {
				compatible = "st,stm32-counter"; /* in zephyr/dts/arm/st/f4/stm32f405.dtsi:107 */
				status = "disabled";             /* in zephyr/dts/arm/st/f4/stm32f405.dtsi:108 */
			};
		};

		/* node '/soc/timers@40010400' defined in zephyr/dts/arm/st/f4/stm32f405.dtsi:112 */
		timers8: timers@40010400 {
			compatible = "st,stm32-timers"; /* in zephyr/dts/arm/st/f4/stm32f405.dtsi:113 */
			reg = < 0x40010400 0x400 >;     /* in zephyr/dts/arm/st/f4/stm32f405.dtsi:114 */
			clocks = < &rcc 0x44 0x2 >,
			         < &rcc 0x16 0xff >;    /* in zephyr/dts/arm/st/f4/stm32f405.dtsi:115 */
			resets = < &rctl 0x481 >;       /* in zephyr/dts/arm/st/f4/stm32f405.dtsi:117 */
			interrupts = < 0x2b 0x0 >,
			             < 0x2c 0x0 >,
			             < 0x2d 0x0 >,
			             < 0x2e 0x0 >;      /* in zephyr/dts/arm/st/f4/stm32f405.dtsi:118 */
			interrupt-names = "brk",
			                  "up",
			                  "trgcom",
			                  "cc";         /* in zephyr/dts/arm/st/f4/stm32f405.dtsi:119 */
			status = "okay";                /* in rbc_main_zephyr/boards/rbc_mainboard/rbc_mainboard.dts:399 */
			st,prescaler = < 0xb3f >;       /* in rbc_main_zephyr/boards/rbc_mainboard/rbc_mainboard.dts:400 */

			/* node '/soc/timers@40010400/pwm' defined in zephyr/dts/arm/st/f4/stm32f405.dtsi:123 */
			pwm {
				compatible = "st,stm32-pwm"; /* in zephyr/dts/arm/st/f4/stm32f405.dtsi:124 */
				status = "disabled";         /* in zephyr/dts/arm/st/f4/stm32f405.dtsi:125 */
				#pwm-cells = < 0x3 >;        /* in zephyr/dts/arm/st/f4/stm32f405.dtsi:126 */
			};

			/* node '/soc/timers@40010400/counter' defined in zephyr/dts/arm/st/f4/stm32f405.dtsi:129 */
			counter8: counter {
				compatible = "st,stm32-counter"; /* in rbc_main_zephyr/boards/rbc_mainboard/rbc_mainboard.dts:403 */
				status = "okay";                 /* in rbc_main_zephyr/boards/rbc_mainboard/rbc_mainboard.dts:404 */
			};

			/* node '/soc/timers@40010400/qdec' defined in zephyr/dts/arm/st/f4/stm32f405.dtsi:134 */
			qdec {
				compatible = "st,stm32-qdec";    /* in zephyr/dts/arm/st/f4/stm32f405.dtsi:135 */
				st,input-filter-level = < 0x0 >; /* in zephyr/dts/arm/st/f4/stm32f405.dtsi:136 */
				status = "disabled";             /* in zephyr/dts/arm/st/f4/stm32f405.dtsi:137 */
			};
		};

		/* node '/soc/timers@40001800' defined in zephyr/dts/arm/st/f4/stm32f405.dtsi:141 */
		timers12: timers@40001800 {
			compatible = "st,stm32-timers"; /* in zephyr/dts/arm/st/f4/stm32f405.dtsi:142 */
			reg = < 0x40001800 0x400 >;     /* in zephyr/dts/arm/st/f4/stm32f405.dtsi:143 */
			clocks = < &rcc 0x40 0x40 >,
			         < &rcc 0x15 0xff >;    /* in zephyr/dts/arm/st/f4/stm32f405.dtsi:144 */
			resets = < &rctl 0x406 >;       /* in zephyr/dts/arm/st/f4/stm32f405.dtsi:146 */
			interrupts = < 0x2b 0x0 >;      /* in zephyr/dts/arm/st/f4/stm32f405.dtsi:147 */
			interrupt-names = "global";     /* in zephyr/dts/arm/st/f4/stm32f405.dtsi:148 */
			st,prescaler = < 0x0 >;         /* in zephyr/dts/arm/st/f4/stm32f405.dtsi:149 */
			status = "okay";                /* in rbc_main_zephyr/boards/rbc_mainboard/rbc_mainboard.dts:431 */

			/* node '/soc/timers@40001800/pwm' defined in zephyr/dts/arm/st/f4/stm32f405.dtsi:152 */
			pwm12: pwm {
				compatible = "st,stm32-pwm";                     /* in rbc_main_zephyr/boards/rbc_mainboard/rbc_mainboard.dts:434 */
				status = "okay";                                 /* in rbc_main_zephyr/boards/rbc_mainboard/rbc_mainboard.dts:435 */
				pinctrl-0 = < &tim12_ch1_pb14 &tim12_ch2_pb15 >; /* in rbc_main_zephyr/boards/rbc_mainboard/rbc_mainboard.dts:436 */
				pinctrl-names = "default";                       /* in rbc_main_zephyr/boards/rbc_mainboard/rbc_mainboard.dts:437 */
				#pwm-cells = < 0x3 >;                            /* in rbc_main_zephyr/boards/rbc_mainboard/rbc_mainboard.dts:438 */
			};

			/* node '/soc/timers@40001800/counter' defined in zephyr/dts/arm/st/f4/stm32f405.dtsi:158 */
			counter {
				compatible = "st,stm32-counter"; /* in zephyr/dts/arm/st/f4/stm32f405.dtsi:159 */
				status = "disabled";             /* in zephyr/dts/arm/st/f4/stm32f405.dtsi:160 */
			};
		};

		/* node '/soc/timers@40001c00' defined in zephyr/dts/arm/st/f4/stm32f405.dtsi:164 */
		timers13: timers@40001c00 {
			compatible = "st,stm32-timers"; /* in zephyr/dts/arm/st/f4/stm32f405.dtsi:165 */
			reg = < 0x40001c00 0x400 >;     /* in zephyr/dts/arm/st/f4/stm32f405.dtsi:166 */
			clocks = < &rcc 0x40 0x80 >,
			         < &rcc 0x15 0xff >;    /* in zephyr/dts/arm/st/f4/stm32f405.dtsi:167 */
			resets = < &rctl 0x407 >;       /* in zephyr/dts/arm/st/f4/stm32f405.dtsi:169 */
			interrupts = < 0x2c 0x0 >;      /* in zephyr/dts/arm/st/f4/stm32f405.dtsi:170 */
			interrupt-names = "global";     /* in zephyr/dts/arm/st/f4/stm32f405.dtsi:171 */
			st,prescaler = < 0x0 >;         /* in zephyr/dts/arm/st/f4/stm32f405.dtsi:172 */
			status = "disabled";            /* in zephyr/dts/arm/st/f4/stm32f405.dtsi:173 */

			/* node '/soc/timers@40001c00/pwm' defined in zephyr/dts/arm/st/f4/stm32f405.dtsi:175 */
			pwm {
				compatible = "st,stm32-pwm"; /* in zephyr/dts/arm/st/f4/stm32f405.dtsi:176 */
				status = "disabled";         /* in zephyr/dts/arm/st/f4/stm32f405.dtsi:177 */
				#pwm-cells = < 0x3 >;        /* in zephyr/dts/arm/st/f4/stm32f405.dtsi:178 */
			};

			/* node '/soc/timers@40001c00/counter' defined in zephyr/dts/arm/st/f4/stm32f405.dtsi:181 */
			counter {
				compatible = "st,stm32-counter"; /* in zephyr/dts/arm/st/f4/stm32f405.dtsi:182 */
				status = "disabled";             /* in zephyr/dts/arm/st/f4/stm32f405.dtsi:183 */
			};
		};

		/* node '/soc/timers@40002000' defined in zephyr/dts/arm/st/f4/stm32f405.dtsi:187 */
		timers14: timers@40002000 {
			compatible = "st,stm32-timers"; /* in zephyr/dts/arm/st/f4/stm32f405.dtsi:188 */
			reg = < 0x40002000 0x400 >;     /* in zephyr/dts/arm/st/f4/stm32f405.dtsi:189 */
			clocks = < &rcc 0x40 0x100 >,
			         < &rcc 0x15 0xff >;    /* in zephyr/dts/arm/st/f4/stm32f405.dtsi:190 */
			resets = < &rctl 0x408 >;       /* in zephyr/dts/arm/st/f4/stm32f405.dtsi:192 */
			interrupts = < 0x2d 0x0 >;      /* in zephyr/dts/arm/st/f4/stm32f405.dtsi:193 */
			interrupt-names = "global";     /* in zephyr/dts/arm/st/f4/stm32f405.dtsi:194 */
			st,prescaler = < 0x0 >;         /* in zephyr/dts/arm/st/f4/stm32f405.dtsi:195 */
			status = "disabled";            /* in zephyr/dts/arm/st/f4/stm32f405.dtsi:196 */

			/* node '/soc/timers@40002000/pwm' defined in zephyr/dts/arm/st/f4/stm32f405.dtsi:198 */
			pwm {
				compatible = "st,stm32-pwm"; /* in zephyr/dts/arm/st/f4/stm32f405.dtsi:199 */
				status = "disabled";         /* in zephyr/dts/arm/st/f4/stm32f405.dtsi:200 */
				#pwm-cells = < 0x3 >;        /* in zephyr/dts/arm/st/f4/stm32f405.dtsi:201 */
			};

			/* node '/soc/timers@40002000/counter' defined in zephyr/dts/arm/st/f4/stm32f405.dtsi:204 */
			counter {
				compatible = "st,stm32-counter"; /* in zephyr/dts/arm/st/f4/stm32f405.dtsi:205 */
				status = "disabled";             /* in zephyr/dts/arm/st/f4/stm32f405.dtsi:206 */
			};
		};

		/* node '/soc/usb@40040000' defined in zephyr/dts/arm/st/f4/stm32f405.dtsi:210 */
		usbotg_hs: usb@40040000 {
			compatible = "st,stm32-otghs";     /* in zephyr/dts/arm/st/f4/stm32f405.dtsi:211 */
			reg = < 0x40040000 0x40000 >;      /* in zephyr/dts/arm/st/f4/stm32f405.dtsi:212 */
			interrupts = < 0x4d 0x0 >,
			             < 0x4a 0x0 >,
			             < 0x4b 0x0 >;         /* in zephyr/dts/arm/st/f4/stm32f405.dtsi:213 */
			interrupt-names = "otghs",
			                  "ep1_out",
			                  "ep1_in";        /* in zephyr/dts/arm/st/f4/stm32f405.dtsi:214 */
			num-bidir-endpoints = < 0x6 >;     /* in zephyr/dts/arm/st/f4/stm32f405.dtsi:215 */
			ram-size = < 0x1000 >;             /* in zephyr/dts/arm/st/f4/stm32f405.dtsi:216 */
			maximum-speed = "full-speed";      /* in zephyr/dts/arm/st/f4/stm32f405.dtsi:217 */
			phys = < &otghs_fs_phy >;          /* in zephyr/dts/arm/st/f4/stm32f405.dtsi:218 */
			clocks = < &rcc 0x30 0x20000000 >,
			         < &rcc 0x7 0xff >;        /* in zephyr/dts/arm/st/f4/stm32f405.dtsi:219 */
			status = "disabled";               /* in zephyr/dts/arm/st/f4/stm32f405.dtsi:221 */
		};

		/* node '/soc/can@40006400' defined in zephyr/dts/arm/st/f4/stm32f405.dtsi:224 */
		can1: can@40006400 {
			compatible = "st,stm32-bxcan";             /* in zephyr/dts/arm/st/f4/stm32f405.dtsi:225 */
			reg = < 0x40006400 0x400 >;                /* in zephyr/dts/arm/st/f4/stm32f405.dtsi:226 */
			interrupts = < 0x13 0x0 >,
			             < 0x14 0x0 >,
			             < 0x15 0x0 >,
			             < 0x16 0x0 >;                 /* in zephyr/dts/arm/st/f4/stm32f405.dtsi:227 */
			interrupt-names = "TX",
			                  "RX0",
			                  "RX1",
			                  "SCE";                   /* in zephyr/dts/arm/st/f4/stm32f405.dtsi:228 */
			clocks = < &rcc 0x40 0x2000000 >;          /* in zephyr/dts/arm/st/f4/stm32f405.dtsi:229 */
			pinctrl-0 = < &can1_rx_pd0 &can1_tx_pd1 >; /* in rbc_main_zephyr/boards/rbc_mainboard/rbc_mainboard.dts:270 */
			pinctrl-names = "default";                 /* in rbc_main_zephyr/boards/rbc_mainboard/rbc_mainboard.dts:271 */
			status = "okay";                           /* in rbc_main_zephyr/boards/rbc_mainboard/rbc_mainboard.dts:272 */
			bus-speed = < 0x89544 >;                   /* in rbc_main_zephyr/boards/rbc_mainboard/rbc_mainboard.dts:274 */
			sample-point = < 0x36b >;                  /* in rbc_main_zephyr/boards/rbc_mainboard/rbc_mainboard.dts:275 */
		};

		/* node '/soc/can@40006800' defined in zephyr/dts/arm/st/f4/stm32f405.dtsi:233 */
		can2: can@40006800 {
			compatible = "st,stm32-bxcan";    /* in zephyr/dts/arm/st/f4/stm32f405.dtsi:234 */
			reg = < 0x40006800 0x400 >;       /* in zephyr/dts/arm/st/f4/stm32f405.dtsi:235 */
			interrupts = < 0x3f 0x0 >,
			             < 0x40 0x0 >,
			             < 0x41 0x0 >,
			             < 0x42 0x0 >;        /* in zephyr/dts/arm/st/f4/stm32f405.dtsi:236 */
			interrupt-names = "TX",
			                  "RX0",
			                  "RX1",
			                  "SCE";          /* in zephyr/dts/arm/st/f4/stm32f405.dtsi:237 */
			clocks = < &rcc 0x40 0x6000000 >; /* in zephyr/dts/arm/st/f4/stm32f405.dtsi:239 */
			master-can-reg = < 0x40006400 >;  /* in zephyr/dts/arm/st/f4/stm32f405.dtsi:240 */
			status = "disabled";              /* in zephyr/dts/arm/st/f4/stm32f405.dtsi:241 */
		};

		/* node '/soc/rng@50060800' defined in zephyr/dts/arm/st/f4/stm32f405.dtsi:244 */
		rng: rng@50060800 {
			compatible = "st,stm32-rng"; /* in zephyr/dts/arm/st/f4/stm32f405.dtsi:245 */
			reg = < 0x50060800 0x400 >;  /* in zephyr/dts/arm/st/f4/stm32f405.dtsi:246 */
			interrupts = < 0x50 0x0 >;   /* in zephyr/dts/arm/st/f4/stm32f405.dtsi:247 */
			clocks = < &rcc 0x34 0x40 >; /* in zephyr/dts/arm/st/f4/stm32f405.dtsi:248 */
			status = "disabled";         /* in zephyr/dts/arm/st/f4/stm32f405.dtsi:249 */
		};

		/* node '/soc/memory@40024000' defined in zephyr/dts/arm/st/f4/stm32f405.dtsi:252 */
		backup_sram: memory@40024000 {
			compatible = "zephyr,memory-region",
			             "st,stm32-backup-sram";  /* in zephyr/dts/arm/st/f4/stm32f405.dtsi:253 */
			reg = < 0x40024000 0x1000 >;          /* in zephyr/dts/arm/st/f4/stm32f405.dtsi:254 */
			clocks = < &rcc 0x30 0x40000 >;       /* in zephyr/dts/arm/st/f4/stm32f405.dtsi:255 */
			zephyr,memory-region = "BACKUP_SRAM"; /* in zephyr/dts/arm/st/f4/stm32f405.dtsi:256 */
			status = "disabled";                  /* in zephyr/dts/arm/st/f4/stm32f405.dtsi:257 */
		};

		/* node '/soc/adc@40012100' defined in zephyr/dts/arm/st/f4/stm32f405.dtsi:260 */
		adc2: adc@40012100 {
			compatible = "st,stm32f4-adc",
			             "st,stm32-adc";                                 /* in zephyr/dts/arm/st/f4/stm32f405.dtsi:261 */
			reg = < 0x40012100 0x50 >;                                   /* in zephyr/dts/arm/st/f4/stm32f405.dtsi:262 */
			clocks = < &rcc 0x44 0x200 >;                                /* in zephyr/dts/arm/st/f4/stm32f405.dtsi:263 */
			clock-names = "adcx";                                        /* in zephyr/dts/arm/st/f4/stm32f405.dtsi:264 */
			interrupts = < 0x12 0x0 >;                                   /* in zephyr/dts/arm/st/f4/stm32f405.dtsi:265 */
			#io-channel-cells = < 0x1 >;                                 /* in zephyr/dts/arm/st/f4/stm32f405.dtsi:266 */
			st,adc-resolutions = < 0xc 0xa 0x8 0x6 >;                    /* in zephyr/dts/arm/st/f4/stm32f405.dtsi:267 */
			sampling-times = < 0x3 0xf 0x1c 0x38 0x54 0x70 0x90 0x1e0 >; /* in zephyr/dts/arm/st/f4/stm32f405.dtsi:268 */
			st,adc-clock-source = "SYNC";                                /* in zephyr/dts/arm/st/f4/stm32f405.dtsi:269 */
			st,adc-sequencer = "programmable";                           /* in zephyr/dts/arm/st/f4/stm32f405.dtsi:270 */
			st,adc-oversampler = "none";                                 /* in zephyr/dts/arm/st/f4/stm32f405.dtsi:271 */
			st,adc-internal-regulator = "none";                          /* in zephyr/dts/arm/st/f4/stm32f405.dtsi:272 */
			st,adc-has-injected-support;                                 /* in zephyr/dts/arm/st/f4/stm32f405.dtsi:273 */
			status = "disabled";                                         /* in zephyr/dts/arm/st/f4/stm32f405.dtsi:274 */
		};

		/* node '/soc/adc@40012200' defined in zephyr/dts/arm/st/f4/stm32f405.dtsi:277 */
		adc3: adc@40012200 {
			compatible = "st,stm32f4-adc",
			             "st,stm32-adc";                                 /* in zephyr/dts/arm/st/f4/stm32f405.dtsi:278 */
			reg = < 0x40012200 0x50 >;                                   /* in zephyr/dts/arm/st/f4/stm32f405.dtsi:279 */
			clocks = < &rcc 0x44 0x400 >;                                /* in zephyr/dts/arm/st/f4/stm32f405.dtsi:280 */
			clock-names = "adcx";                                        /* in zephyr/dts/arm/st/f4/stm32f405.dtsi:281 */
			interrupts = < 0x12 0x0 >;                                   /* in zephyr/dts/arm/st/f4/stm32f405.dtsi:282 */
			#io-channel-cells = < 0x1 >;                                 /* in zephyr/dts/arm/st/f4/stm32f405.dtsi:283 */
			st,adc-resolutions = < 0xc 0xa 0x8 0x6 >;                    /* in zephyr/dts/arm/st/f4/stm32f405.dtsi:284 */
			sampling-times = < 0x3 0xf 0x1c 0x38 0x54 0x70 0x90 0x1e0 >; /* in zephyr/dts/arm/st/f4/stm32f405.dtsi:285 */
			st,adc-clock-source = "SYNC";                                /* in zephyr/dts/arm/st/f4/stm32f405.dtsi:286 */
			st,adc-sequencer = "programmable";                           /* in zephyr/dts/arm/st/f4/stm32f405.dtsi:287 */
			st,adc-oversampler = "none";                                 /* in zephyr/dts/arm/st/f4/stm32f405.dtsi:288 */
			st,adc-internal-regulator = "none";                          /* in zephyr/dts/arm/st/f4/stm32f405.dtsi:289 */
			st,adc-has-injected-support;                                 /* in zephyr/dts/arm/st/f4/stm32f405.dtsi:290 */
			status = "disabled";                                         /* in zephyr/dts/arm/st/f4/stm32f405.dtsi:291 */
		};

		/* node '/soc/dac@40007400' defined in zephyr/dts/arm/st/f4/stm32f405.dtsi:294 */
		dac1: dac@40007400 {
			compatible = "st,stm32-dac";       /* in zephyr/dts/arm/st/f4/stm32f405.dtsi:295 */
			reg = < 0x40007400 0x400 >;        /* in zephyr/dts/arm/st/f4/stm32f405.dtsi:296 */
			clocks = < &rcc 0x40 0x20000000 >; /* in zephyr/dts/arm/st/f4/stm32f405.dtsi:297 */
			status = "disabled";               /* in zephyr/dts/arm/st/f4/stm32f405.dtsi:298 */
			#io-channel-cells = < 0x1 >;       /* in zephyr/dts/arm/st/f4/stm32f405.dtsi:299 */
		};

		/* node '/soc/ethernet@40028000' defined in zephyr/dts/arm/st/f4/stm32f407.dtsi:13 */
		mac: ethernet@40028000 {
			compatible = "st,stm32-ethernet";  /* in zephyr/dts/arm/st/f4/stm32f407.dtsi:14 */
			reg = < 0x40028000 0x8000 >;       /* in zephyr/dts/arm/st/f4/stm32f407.dtsi:15 */
			clock-names = "stm-eth",
			              "mac-clk-tx",
			              "mac-clk-rx",
			              "mac-clk-ptp";       /* in zephyr/dts/arm/st/f4/stm32f407.dtsi:16 */
			clocks = < &rcc 0x30 0x2000000 >,
			         < &rcc 0x30 0x4000000 >,
			         < &rcc 0x30 0x8000000 >,
			         < &rcc 0x30 0x10000000 >; /* in zephyr/dts/arm/st/f4/stm32f407.dtsi:17 */
			interrupts = < 0x3d 0x0 >;         /* in zephyr/dts/arm/st/f4/stm32f407.dtsi:21 */
			status = "disabled";               /* in zephyr/dts/arm/st/f4/stm32f407.dtsi:22 */

			/* node '/soc/ethernet@40028000/mdio' defined in zephyr/dts/arm/st/f4/stm32f407.dtsi:24 */
			mdio: mdio {
				compatible = "st,stm32-mdio"; /* in zephyr/dts/arm/st/f4/stm32f407.dtsi:25 */
				#address-cells = < 0x1 >;     /* in zephyr/dts/arm/st/f4/stm32f407.dtsi:26 */
				#size-cells = < 0x0 >;        /* in zephyr/dts/arm/st/f4/stm32f407.dtsi:27 */
				status = "disabled";          /* in zephyr/dts/arm/st/f4/stm32f407.dtsi:28 */
			};
		};
	};

	/* node '/cpus' defined in zephyr/dts/arm/st/f4/stm32f4.dtsi:30 */
	cpus {
		#address-cells = < 0x1 >; /* in zephyr/dts/arm/st/f4/stm32f4.dtsi:31 */
		#size-cells = < 0x0 >;    /* in zephyr/dts/arm/st/f4/stm32f4.dtsi:32 */

		/* node '/cpus/cpu@0' defined in zephyr/dts/arm/st/f4/stm32f4.dtsi:34 */
		cpu0: cpu@0 {
			device_type = "cpu";           /* in zephyr/dts/arm/st/f4/stm32f4.dtsi:35 */
			compatible = "arm,cortex-m4f"; /* in zephyr/dts/arm/st/f4/stm32f4.dtsi:36 */
			reg = < 0x0 >;                 /* in zephyr/dts/arm/st/f4/stm32f4.dtsi:37 */
			cpu-power-states = < &stop >;  /* in zephyr/dts/arm/st/f4/stm32f4.dtsi:38 */
		};

		/* node '/cpus/power-states' defined in zephyr/dts/arm/st/f4/stm32f4.dtsi:41 */
		power-states {

			/* node '/cpus/power-states/stop' defined in zephyr/dts/arm/st/f4/stm32f4.dtsi:42 */
			stop: stop {
				compatible = "zephyr,power-state";    /* in zephyr/dts/arm/st/f4/stm32f4.dtsi:43 */
				power-state-name = "suspend-to-idle"; /* in zephyr/dts/arm/st/f4/stm32f4.dtsi:44 */
				min-residency-us = < 0x190 >;         /* in zephyr/dts/arm/st/f4/stm32f4.dtsi:51 */
				exit-latency-us = < 0x12c >;          /* in zephyr/dts/arm/st/f4/stm32f4.dtsi:52 */
				phandle = < 0x23 >;                   /* in zephyr/dts/arm/st/f4/stm32f4.dtsi:38 */
			};
		};
	};

	/* node '/memory@20000000' defined in zephyr/dts/arm/st/f4/stm32f4.dtsi:57 */
	sram0: memory@20000000 {
		compatible = "zephyr,memory-region",
		             "mmio-sram";            /* in zephyr/dts/arm/st/f4/stm32f4.dtsi:58 */
		zephyr,memory-region = "SRAM0";      /* in zephyr/dts/arm/st/f4/stm32f4.dtsi:59 */
		reg = < 0x20000000 0x20000 >;        /* in zephyr/dts/arm/st/f4/stm32f407Xg.dtsi:17 */
	};

	/* node '/clocks' defined in zephyr/dts/arm/st/f4/stm32f4.dtsi:62 */
	clocks {

		/* node '/clocks/clk-hse' defined in zephyr/dts/arm/st/f4/stm32f4.dtsi:63 */
		clk_hse: clk-hse {
			#clock-cells = < 0x0 >;            /* in zephyr/dts/arm/st/f4/stm32f4.dtsi:64 */
			compatible = "st,stm32-hse-clock"; /* in zephyr/dts/arm/st/f4/stm32f4.dtsi:65 */
			clock-frequency = < 0x7a1200 >;    /* in rbc_main_zephyr/boards/rbc_mainboard/rbc_mainboard.dts:206 */
			status = "okay";                   /* in rbc_main_zephyr/boards/rbc_mainboard/rbc_mainboard.dts:207 */
			phandle = < 0x24 >;                /* in rbc_main_zephyr/boards/rbc_mainboard/rbc_mainboard.dts:215 */
		};

		/* node '/clocks/clk-hsi' defined in zephyr/dts/arm/st/f4/stm32f4.dtsi:69 */
		clk_hsi: clk-hsi {
			#clock-cells = < 0x0 >;         /* in zephyr/dts/arm/st/f4/stm32f4.dtsi:70 */
			compatible = "fixed-clock";     /* in zephyr/dts/arm/st/f4/stm32f4.dtsi:71 */
			clock-frequency = < 0xf42400 >; /* in zephyr/dts/arm/st/f4/stm32f4.dtsi:72 */
			status = "disabled";            /* in zephyr/dts/arm/st/f4/stm32f4.dtsi:73 */
		};

		/* node '/clocks/clk-lse' defined in zephyr/dts/arm/st/f4/stm32f4.dtsi:76 */
		clk_lse: clk-lse {
			#clock-cells = < 0x0 >;       /* in zephyr/dts/arm/st/f4/stm32f4.dtsi:77 */
			compatible = "fixed-clock";   /* in zephyr/dts/arm/st/f4/stm32f4.dtsi:78 */
			clock-frequency = < 0x8000 >; /* in zephyr/dts/arm/st/f4/stm32f4.dtsi:79 */
			status = "disabled";          /* in zephyr/dts/arm/st/f4/stm32f4.dtsi:80 */
		};

		/* node '/clocks/clk-lsi' defined in zephyr/dts/arm/st/f4/stm32f4.dtsi:83 */
		clk_lsi: clk-lsi {
			#clock-cells = < 0x0 >;       /* in zephyr/dts/arm/st/f4/stm32f4.dtsi:84 */
			compatible = "fixed-clock";   /* in zephyr/dts/arm/st/f4/stm32f4.dtsi:85 */
			clock-frequency = < 0x7d00 >; /* in zephyr/dts/arm/st/f4/stm32f4.dtsi:86 */
			status = "disabled";          /* in zephyr/dts/arm/st/f4/stm32f4.dtsi:87 */
		};

		/* node '/clocks/pll' defined in zephyr/dts/arm/st/f4/stm32f4.dtsi:90 */
		pll: pll {
			#clock-cells = < 0x0 >;              /* in zephyr/dts/arm/st/f4/stm32f4.dtsi:91 */
			compatible = "st,stm32fx-pll-clock"; /* in zephyr/dts/arm/st/f4/stm32f4.dtsi:92 */
			div-m = < 0x4 >;                     /* in rbc_main_zephyr/boards/rbc_mainboard/rbc_mainboard.dts:211 */
			mul-n = < 0x90 >;                    /* in rbc_main_zephyr/boards/rbc_mainboard/rbc_mainboard.dts:212 */
			div-p = < 0x2 >;                     /* in rbc_main_zephyr/boards/rbc_mainboard/rbc_mainboard.dts:213 */
			div-q = < 0x6 >;                     /* in rbc_main_zephyr/boards/rbc_mainboard/rbc_mainboard.dts:214 */
			clocks = < &clk_hse >;               /* in rbc_main_zephyr/boards/rbc_mainboard/rbc_mainboard.dts:215 */
			status = "okay";                     /* in rbc_main_zephyr/boards/rbc_mainboard/rbc_mainboard.dts:216 */
			phandle = < 0x2 >;                   /* in rbc_main_zephyr/boards/rbc_mainboard/rbc_mainboard.dts:220 */
		};

		/* node '/clocks/plli2s' defined in zephyr/dts/arm/st/f4/stm32f401.dtsi:11 */
		plli2s: plli2s {
			#clock-cells = < 0x0 >;              /* in zephyr/dts/arm/st/f4/stm32f401.dtsi:12 */
			compatible = "st,stm32fx-pll-clock"; /* in zephyr/dts/arm/st/f4/stm32f401.dtsi:13 */
			status = "disabled";                 /* in zephyr/dts/arm/st/f4/stm32f401.dtsi:14 */
		};
	};

	/* node '/mcos' defined in zephyr/dts/arm/st/f4/stm32f4.dtsi:97 */
	mcos {

		/* node '/mcos/mco1' defined in zephyr/dts/arm/st/f4/stm32f4.dtsi:98 */
		mco1: mco1 {
			compatible = "st,stm32-clock-mco"; /* in zephyr/dts/arm/st/f4/stm32f4.dtsi:99 */
			clock-names = "clksel";            /* in zephyr/dts/arm/st/f4/stm32f4.dtsi:100 */
			status = "disabled";               /* in zephyr/dts/arm/st/f4/stm32f4.dtsi:101 */
		};

		/* node '/mcos/mco2' defined in zephyr/dts/arm/st/f4/stm32f4.dtsi:104 */
		mco2: mco2 {
			compatible = "st,stm32-clock-mco"; /* in zephyr/dts/arm/st/f4/stm32f4.dtsi:105 */
			clock-names = "clksel";            /* in zephyr/dts/arm/st/f4/stm32f4.dtsi:106 */
			status = "disabled";               /* in zephyr/dts/arm/st/f4/stm32f4.dtsi:107 */
		};
	};

	/* node '/power@40007000' defined in zephyr/dts/arm/st/f4/stm32f4.dtsi:656 */
	pwr: power@40007000 {
		compatible = "st,stm32-pwr"; /* in zephyr/dts/arm/st/f4/stm32f4.dtsi:657 */
		reg = < 0x40007000 0x400 >;  /* in zephyr/dts/arm/st/f4/stm32f4.dtsi:658 */
		status = "disabled";         /* in zephyr/dts/arm/st/f4/stm32f4.dtsi:659 */
		wkup-pins-nb = < 0x1 >;      /* in zephyr/dts/arm/st/f4/stm32f4.dtsi:661 */
		#address-cells = < 0x1 >;    /* in zephyr/dts/arm/st/f4/stm32f4.dtsi:663 */
		#size-cells = < 0x0 >;       /* in zephyr/dts/arm/st/f4/stm32f4.dtsi:664 */

		/* node '/power@40007000/wkup-pin@1' defined in zephyr/dts/arm/st/f4/stm32f4.dtsi:666 */
		wkup-pin@1 {
			reg = < 0x1 >;                   /* in zephyr/dts/arm/st/f4/stm32f4.dtsi:667 */
			wkup-gpios = < &gpioa 0x0 0x1 >; /* in zephyr/dts/arm/st/f4/stm32f4.dtsi:668 */
		};
	};

	/* node '/dietemp' defined in zephyr/dts/arm/st/f4/stm32f4.dtsi:672 */
	die_temp: dietemp {
		compatible = "st,stm32-temp-cal"; /* in zephyr/dts/arm/st/f4/stm32f4.dtsi:673 */
		nvmem-cells = < &ts_cal1_otp >,
		              < &ts_cal2_otp >;   /* in zephyr/dts/arm/st/f4/stm32f4.dtsi:674 */
		nvmem-cell-names = "TS_CAL1",
		                   "TS_CAL2";     /* in zephyr/dts/arm/st/f4/stm32f4.dtsi:675 */
		ts-cal1-temp = < 0x1e >;          /* in zephyr/dts/arm/st/f4/stm32f4.dtsi:676 */
		ts-cal2-temp = < 0x6e >;          /* in zephyr/dts/arm/st/f4/stm32f4.dtsi:677 */
		ts-cal-vrefanalog = < 0xce4 >;    /* in zephyr/dts/arm/st/f4/stm32f4.dtsi:678 */
		io-channels = < &adc1 0x10 >;     /* in zephyr/dts/arm/st/f4/stm32f4.dtsi:679 */
		status = "disabled";              /* in zephyr/dts/arm/st/f4/stm32f4.dtsi:680 */
	};

	/* node '/vref' defined in zephyr/dts/arm/st/f4/stm32f4.dtsi:683 */
	vref: vref {
		compatible = "st,stm32-vref";   /* in zephyr/dts/arm/st/f4/stm32f4.dtsi:684 */
		nvmem-cells = < &vrefint_otp >; /* in zephyr/dts/arm/st/f4/stm32f4.dtsi:685 */
		vrefint-cal-mv = < 0xce4 >;     /* in zephyr/dts/arm/st/f4/stm32f4.dtsi:686 */
		io-channels = < &adc1 0x11 >;   /* in zephyr/dts/arm/st/f4/stm32f4.dtsi:687 */
		status = "disabled";            /* in zephyr/dts/arm/st/f4/stm32f4.dtsi:688 */
	};

	/* node '/vbat' defined in zephyr/dts/arm/st/f4/stm32f4.dtsi:691 */
	vbat: vbat {
		compatible = "st,stm32-vbat"; /* in zephyr/dts/arm/st/f4/stm32f4.dtsi:692 */
		ratio = < 0x4 >;              /* in zephyr/dts/arm/st/f4/stm32f4.dtsi:693 */
		io-channels = < &adc1 0x12 >; /* in zephyr/dts/arm/st/f4/stm32f4.dtsi:694 */
		status = "disabled";          /* in zephyr/dts/arm/st/f4/stm32f4.dtsi:695 */
	};

	/* node '/otgfs_phy' defined in zephyr/dts/arm/st/f4/stm32f4.dtsi:698 */
	otgfs_phy: otgfs_phy {
		compatible = "usb-nop-xceiv"; /* in zephyr/dts/arm/st/f4/stm32f4.dtsi:699 */
		#phy-cells = < 0x0 >;         /* in zephyr/dts/arm/st/f4/stm32f4.dtsi:700 */
		phandle = < 0x10 >;           /* in zephyr/dts/arm/st/f4/stm32f4.dtsi:372 */
	};

	/* node '/smbus1' defined in zephyr/dts/arm/st/f4/stm32f4.dtsi:703 */
	smbus1: smbus1 {
		compatible = "st,stm32-smbus"; /* in zephyr/dts/arm/st/f4/stm32f4.dtsi:704 */
		#address-cells = < 0x1 >;      /* in zephyr/dts/arm/st/f4/stm32f4.dtsi:705 */
		#size-cells = < 0x0 >;         /* in zephyr/dts/arm/st/f4/stm32f4.dtsi:706 */
		i2c = < &i2c1 >;               /* in zephyr/dts/arm/st/f4/stm32f4.dtsi:707 */
		status = "disabled";           /* in zephyr/dts/arm/st/f4/stm32f4.dtsi:708 */
	};

	/* node '/smbus2' defined in zephyr/dts/arm/st/f4/stm32f4.dtsi:711 */
	smbus2: smbus2 {
		compatible = "st,stm32-smbus"; /* in zephyr/dts/arm/st/f4/stm32f4.dtsi:712 */
		#address-cells = < 0x1 >;      /* in zephyr/dts/arm/st/f4/stm32f4.dtsi:713 */
		#size-cells = < 0x0 >;         /* in zephyr/dts/arm/st/f4/stm32f4.dtsi:714 */
		i2c = < &i2c2 >;               /* in zephyr/dts/arm/st/f4/stm32f4.dtsi:715 */
		status = "disabled";           /* in zephyr/dts/arm/st/f4/stm32f4.dtsi:716 */
	};

	/* node '/smbus3' defined in zephyr/dts/arm/st/f4/stm32f4.dtsi:719 */
	smbus3: smbus3 {
		compatible = "st,stm32-smbus"; /* in zephyr/dts/arm/st/f4/stm32f4.dtsi:720 */
		#address-cells = < 0x1 >;      /* in zephyr/dts/arm/st/f4/stm32f4.dtsi:721 */
		#size-cells = < 0x0 >;         /* in zephyr/dts/arm/st/f4/stm32f4.dtsi:722 */
		i2c = < &i2c3 >;               /* in zephyr/dts/arm/st/f4/stm32f4.dtsi:723 */
		status = "disabled";           /* in zephyr/dts/arm/st/f4/stm32f4.dtsi:724 */
	};

	/* node '/otghs_fs_phy' defined in zephyr/dts/arm/st/f4/stm32f405.dtsi:303 */
	otghs_fs_phy: otghs_fs_phy {
		compatible = "usb-nop-xceiv"; /* in zephyr/dts/arm/st/f4/stm32f405.dtsi:304 */
		#phy-cells = < 0x0 >;         /* in zephyr/dts/arm/st/f4/stm32f405.dtsi:305 */
		phandle = < 0x20 >;           /* in zephyr/dts/arm/st/f4/stm32f405.dtsi:218 */
	};

	/* node '/memory@10000000' defined in zephyr/dts/arm/st/f4/stm32f407Xg.dtsi:10 */
	ccm0: memory@10000000 {
		compatible = "zephyr,memory-region",
		             "st,stm32-ccm";         /* in zephyr/dts/arm/st/f4/stm32f407Xg.dtsi:11 */
		reg = < 0x10000000 0x10000 >;        /* in zephyr/dts/arm/st/f4/stm32f407Xg.dtsi:12 */
		zephyr,memory-region = "DTCM";       /* in zephyr/dts/arm/st/f4/stm32f407Xg.dtsi:13 */
	};

	/* node '/leds' defined in rbc_main_zephyr/boards/rbc_mainboard/rbc_mainboard.dts:33 */
	leds {
		compatible = "gpio-leds"; /* in rbc_main_zephyr/boards/rbc_mainboard/rbc_mainboard.dts:34 */

		/* node '/leds/led_pc13' defined in rbc_main_zephyr/boards/rbc_mainboard/rbc_mainboard.dts:36 */
		led0: led_pc13 {
			gpios = < &gpioc 0xd 0x1 >; /* in rbc_main_zephyr/boards/rbc_mainboard/rbc_mainboard.dts:37 */
			label = "LED PC13";         /* in rbc_main_zephyr/boards/rbc_mainboard/rbc_mainboard.dts:38 */
		};

		/* node '/leds/led_pc14' defined in rbc_main_zephyr/boards/rbc_mainboard/rbc_mainboard.dts:41 */
		led1: led_pc14 {
			gpios = < &gpioc 0xe 0x1 >; /* in rbc_main_zephyr/boards/rbc_mainboard/rbc_mainboard.dts:42 */
			label = "LED PC14";         /* in rbc_main_zephyr/boards/rbc_mainboard/rbc_mainboard.dts:43 */
		};

		/* node '/leds/led_pc15' defined in rbc_main_zephyr/boards/rbc_mainboard/rbc_mainboard.dts:46 */
		led2: led_pc15 {
			gpios = < &gpioc 0xf 0x1 >; /* in rbc_main_zephyr/boards/rbc_mainboard/rbc_mainboard.dts:47 */
			label = "LED PC15";         /* in rbc_main_zephyr/boards/rbc_mainboard/rbc_mainboard.dts:48 */
		};
	};

	/* node '/gpio_keys' defined in rbc_main_zephyr/boards/rbc_mainboard/rbc_mainboard.dts:57 */
	gpio_keys {
		compatible = "gpio-keys"; /* in rbc_main_zephyr/boards/rbc_mainboard/rbc_mainboard.dts:58 */

		/* node '/gpio_keys/button_1' defined in rbc_main_zephyr/boards/rbc_mainboard/rbc_mainboard.dts:60 */
		btn1: button_1 {
			label = "BTN1";              /* in rbc_main_zephyr/boards/rbc_mainboard/rbc_mainboard.dts:61 */
			gpios = < &gpioe 0x4 0x11 >; /* in rbc_main_zephyr/boards/rbc_mainboard/rbc_mainboard.dts:62 */
			zephyr,code = < 0xb >;       /* in rbc_main_zephyr/boards/rbc_mainboard/rbc_mainboard.dts:63 */
		};

		/* node '/gpio_keys/button_2' defined in rbc_main_zephyr/boards/rbc_mainboard/rbc_mainboard.dts:66 */
		btn2: button_2 {
			label = "BTN2";              /* in rbc_main_zephyr/boards/rbc_mainboard/rbc_mainboard.dts:67 */
			gpios = < &gpioe 0x5 0x11 >; /* in rbc_main_zephyr/boards/rbc_mainboard/rbc_mainboard.dts:68 */
			zephyr,code = < 0x2 >;       /* in rbc_main_zephyr/boards/rbc_mainboard/rbc_mainboard.dts:69 */
		};
	};

	/* node '/digital_inputs' defined in rbc_main_zephyr/boards/rbc_mainboard/rbc_mainboard.dts:79 */
	digital_inputs {
		compatible = "gpio-keys"; /* in rbc_main_zephyr/boards/rbc_mainboard/rbc_mainboard.dts:80 */

		/* node '/digital_inputs/input_1' defined in rbc_main_zephyr/boards/rbc_mainboard/rbc_mainboard.dts:82 */
		in1: input_1 {
			gpios = < &gpioc 0xa 0x1 >; /* in rbc_main_zephyr/boards/rbc_mainboard/rbc_mainboard.dts:83 */
			label = "IN1";              /* in rbc_main_zephyr/boards/rbc_mainboard/rbc_mainboard.dts:84 */
			zephyr,code = < 0x3 >;      /* in rbc_main_zephyr/boards/rbc_mainboard/rbc_mainboard.dts:85 */
		};

		/* node '/digital_inputs/input_2' defined in rbc_main_zephyr/boards/rbc_mainboard/rbc_mainboard.dts:87 */
		in2: input_2 {
			gpios = < &gpioc 0xb 0x1 >; /* in rbc_main_zephyr/boards/rbc_mainboard/rbc_mainboard.dts:88 */
			label = "IN2";              /* in rbc_main_zephyr/boards/rbc_mainboard/rbc_mainboard.dts:89 */
			zephyr,code = < 0x4 >;      /* in rbc_main_zephyr/boards/rbc_mainboard/rbc_mainboard.dts:90 */
		};

		/* node '/digital_inputs/input_3' defined in rbc_main_zephyr/boards/rbc_mainboard/rbc_mainboard.dts:92 */
		in3: input_3 {
			gpios = < &gpioc 0xc 0x1 >; /* in rbc_main_zephyr/boards/rbc_mainboard/rbc_mainboard.dts:93 */
			label = "IN3";              /* in rbc_main_zephyr/boards/rbc_mainboard/rbc_mainboard.dts:94 */
			zephyr,code = < 0x5 >;      /* in rbc_main_zephyr/boards/rbc_mainboard/rbc_mainboard.dts:95 */
		};

		/* node '/digital_inputs/input_4' defined in rbc_main_zephyr/boards/rbc_mainboard/rbc_mainboard.dts:97 */
		in4: input_4 {
			gpios = < &gpiod 0x7 0x1 >; /* in rbc_main_zephyr/boards/rbc_mainboard/rbc_mainboard.dts:98 */
			label = "IN4";              /* in rbc_main_zephyr/boards/rbc_mainboard/rbc_mainboard.dts:99 */
			zephyr,code = < 0x6 >;      /* in rbc_main_zephyr/boards/rbc_mainboard/rbc_mainboard.dts:100 */
		};

		/* node '/digital_inputs/input_5' defined in rbc_main_zephyr/boards/rbc_mainboard/rbc_mainboard.dts:102 */
		in5: input_5 {
			gpios = < &gpiob 0x4 0x1 >; /* in rbc_main_zephyr/boards/rbc_mainboard/rbc_mainboard.dts:103 */
			label = "IN5";              /* in rbc_main_zephyr/boards/rbc_mainboard/rbc_mainboard.dts:104 */
			zephyr,code = < 0x7 >;      /* in rbc_main_zephyr/boards/rbc_mainboard/rbc_mainboard.dts:105 */
		};

		/* node '/digital_inputs/input_6' defined in rbc_main_zephyr/boards/rbc_mainboard/rbc_mainboard.dts:107 */
		in6: input_6 {
			gpios = < &gpiob 0x5 0x1 >; /* in rbc_main_zephyr/boards/rbc_mainboard/rbc_mainboard.dts:108 */
			label = "IN6";              /* in rbc_main_zephyr/boards/rbc_mainboard/rbc_mainboard.dts:109 */
			zephyr,code = < 0x8 >;      /* in rbc_main_zephyr/boards/rbc_mainboard/rbc_mainboard.dts:110 */
		};

		/* node '/digital_inputs/input_7' defined in rbc_main_zephyr/boards/rbc_mainboard/rbc_mainboard.dts:112 */
		in7: input_7 {
			gpios = < &gpiob 0x8 0x1 >; /* in rbc_main_zephyr/boards/rbc_mainboard/rbc_mainboard.dts:113 */
			label = "IN7";              /* in rbc_main_zephyr/boards/rbc_mainboard/rbc_mainboard.dts:114 */
			zephyr,code = < 0x9 >;      /* in rbc_main_zephyr/boards/rbc_mainboard/rbc_mainboard.dts:115 */
		};

		/* node '/digital_inputs/input_8' defined in rbc_main_zephyr/boards/rbc_mainboard/rbc_mainboard.dts:117 */
		in8: input_8 {
			gpios = < &gpiob 0x9 0x1 >; /* in rbc_main_zephyr/boards/rbc_mainboard/rbc_mainboard.dts:118 */
			label = "IN8";              /* in rbc_main_zephyr/boards/rbc_mainboard/rbc_mainboard.dts:119 */
			zephyr,code = < 0xa >;      /* in rbc_main_zephyr/boards/rbc_mainboard/rbc_mainboard.dts:120 */
		};

		/* node '/digital_inputs/input_9' defined in rbc_main_zephyr/boards/rbc_mainboard/rbc_mainboard.dts:122 */
		in9: input_9 {
			gpios = < &gpioe 0x0 0x1 >; /* in rbc_main_zephyr/boards/rbc_mainboard/rbc_mainboard.dts:123 */
			label = "IN9";              /* in rbc_main_zephyr/boards/rbc_mainboard/rbc_mainboard.dts:124 */
			zephyr,code = < 0x1e >;     /* in rbc_main_zephyr/boards/rbc_mainboard/rbc_mainboard.dts:125 */
		};

		/* node '/digital_inputs/input_10' defined in rbc_main_zephyr/boards/rbc_mainboard/rbc_mainboard.dts:127 */
		in10: input_10 {
			gpios = < &gpioe 0x1 0x1 >; /* in rbc_main_zephyr/boards/rbc_mainboard/rbc_mainboard.dts:128 */
			label = "IN10";             /* in rbc_main_zephyr/boards/rbc_mainboard/rbc_mainboard.dts:129 */
			zephyr,code = < 0x30 >;     /* in rbc_main_zephyr/boards/rbc_mainboard/rbc_mainboard.dts:130 */
		};
	};

	/* node '/digital_outputs' defined in rbc_main_zephyr/boards/rbc_mainboard/rbc_mainboard.dts:140 */
	digital_outputs {
		compatible = "gpio-leds"; /* in rbc_main_zephyr/boards/rbc_mainboard/rbc_mainboard.dts:141 */

		/* node '/digital_outputs/mux_s0' defined in rbc_main_zephyr/boards/rbc_mainboard/rbc_mainboard.dts:144 */
		s0: mux_s0 {
			gpios = < &gpioa 0x1 0x0 >; /* in rbc_main_zephyr/boards/rbc_mainboard/rbc_mainboard.dts:144 */
			label = "S0";               /* in rbc_main_zephyr/boards/rbc_mainboard/rbc_mainboard.dts:144 */
		};

		/* node '/digital_outputs/mux_s1' defined in rbc_main_zephyr/boards/rbc_mainboard/rbc_mainboard.dts:145 */
		s1: mux_s1 {
			gpios = < &gpioa 0x2 0x0 >; /* in rbc_main_zephyr/boards/rbc_mainboard/rbc_mainboard.dts:145 */
			label = "S1";               /* in rbc_main_zephyr/boards/rbc_mainboard/rbc_mainboard.dts:145 */
		};

		/* node '/digital_outputs/mux_s2' defined in rbc_main_zephyr/boards/rbc_mainboard/rbc_mainboard.dts:146 */
		s2: mux_s2 {
			gpios = < &gpioa 0x3 0x0 >; /* in rbc_main_zephyr/boards/rbc_mainboard/rbc_mainboard.dts:146 */
			label = "S2";               /* in rbc_main_zephyr/boards/rbc_mainboard/rbc_mainboard.dts:146 */
		};

		/* node '/digital_outputs/mux_s3' defined in rbc_main_zephyr/boards/rbc_mainboard/rbc_mainboard.dts:147 */
		s3: mux_s3 {
			gpios = < &gpioa 0x4 0x0 >; /* in rbc_main_zephyr/boards/rbc_mainboard/rbc_mainboard.dts:147 */
			label = "S3";               /* in rbc_main_zephyr/boards/rbc_mainboard/rbc_mainboard.dts:147 */
		};

		/* node '/digital_outputs/out_1' defined in rbc_main_zephyr/boards/rbc_mainboard/rbc_mainboard.dts:150 */
		o1: out_1 {
			gpios = < &gpiob 0x1 0x1 >; /* in rbc_main_zephyr/boards/rbc_mainboard/rbc_mainboard.dts:150 */
			label = "O1";               /* in rbc_main_zephyr/boards/rbc_mainboard/rbc_mainboard.dts:150 */
		};

		/* node '/digital_outputs/out_2' defined in rbc_main_zephyr/boards/rbc_mainboard/rbc_mainboard.dts:151 */
		o2: out_2 {
			gpios = < &gpioe 0x7 0x1 >; /* in rbc_main_zephyr/boards/rbc_mainboard/rbc_mainboard.dts:151 */
			label = "O2";               /* in rbc_main_zephyr/boards/rbc_mainboard/rbc_mainboard.dts:151 */
		};

		/* node '/digital_outputs/out_3' defined in rbc_main_zephyr/boards/rbc_mainboard/rbc_mainboard.dts:152 */
		o3: out_3 {
			gpios = < &gpioe 0x8 0x1 >; /* in rbc_main_zephyr/boards/rbc_mainboard/rbc_mainboard.dts:152 */
			label = "O3";               /* in rbc_main_zephyr/boards/rbc_mainboard/rbc_mainboard.dts:152 */
		};

		/* node '/digital_outputs/out_4' defined in rbc_main_zephyr/boards/rbc_mainboard/rbc_mainboard.dts:153 */
		o4: out_4 {
			gpios = < &gpioe 0x9 0x1 >; /* in rbc_main_zephyr/boards/rbc_mainboard/rbc_mainboard.dts:153 */
			label = "O4";               /* in rbc_main_zephyr/boards/rbc_mainboard/rbc_mainboard.dts:153 */
		};

		/* node '/digital_outputs/out_5' defined in rbc_main_zephyr/boards/rbc_mainboard/rbc_mainboard.dts:154 */
		o5: out_5 {
			gpios = < &gpioe 0xa 0x1 >; /* in rbc_main_zephyr/boards/rbc_mainboard/rbc_mainboard.dts:154 */
			label = "O5";               /* in rbc_main_zephyr/boards/rbc_mainboard/rbc_mainboard.dts:154 */
		};

		/* node '/digital_outputs/out_6' defined in rbc_main_zephyr/boards/rbc_mainboard/rbc_mainboard.dts:155 */
		o6: out_6 {
			gpios = < &gpioe 0xb 0x1 >; /* in rbc_main_zephyr/boards/rbc_mainboard/rbc_mainboard.dts:155 */
			label = "O6";               /* in rbc_main_zephyr/boards/rbc_mainboard/rbc_mainboard.dts:155 */
		};

		/* node '/digital_outputs/out_7' defined in rbc_main_zephyr/boards/rbc_mainboard/rbc_mainboard.dts:156 */
		o7: out_7 {
			gpios = < &gpioe 0xc 0x1 >; /* in rbc_main_zephyr/boards/rbc_mainboard/rbc_mainboard.dts:156 */
			label = "O7";               /* in rbc_main_zephyr/boards/rbc_mainboard/rbc_mainboard.dts:156 */
		};

		/* node '/digital_outputs/out_8' defined in rbc_main_zephyr/boards/rbc_mainboard/rbc_mainboard.dts:157 */
		o8: out_8 {
			gpios = < &gpioe 0xd 0x1 >; /* in rbc_main_zephyr/boards/rbc_mainboard/rbc_mainboard.dts:157 */
			label = "O8";               /* in rbc_main_zephyr/boards/rbc_mainboard/rbc_mainboard.dts:157 */
		};

		/* node '/digital_outputs/out_9' defined in rbc_main_zephyr/boards/rbc_mainboard/rbc_mainboard.dts:158 */
		o9: out_9 {
			gpios = < &gpioe 0xe 0x1 >; /* in rbc_main_zephyr/boards/rbc_mainboard/rbc_mainboard.dts:158 */
			label = "O9";               /* in rbc_main_zephyr/boards/rbc_mainboard/rbc_mainboard.dts:158 */
		};

		/* node '/digital_outputs/out_10' defined in rbc_main_zephyr/boards/rbc_mainboard/rbc_mainboard.dts:159 */
		o10: out_10 {
			gpios = < &gpioe 0xf 0x1 >; /* in rbc_main_zephyr/boards/rbc_mainboard/rbc_mainboard.dts:159 */
			label = "O10";              /* in rbc_main_zephyr/boards/rbc_mainboard/rbc_mainboard.dts:159 */
		};

		/* node '/digital_outputs/out_11' defined in rbc_main_zephyr/boards/rbc_mainboard/rbc_mainboard.dts:160 */
		o11: out_11 {
			gpios = < &gpioc 0x3 0x1 >; /* in rbc_main_zephyr/boards/rbc_mainboard/rbc_mainboard.dts:160 */
			label = "O11";              /* in rbc_main_zephyr/boards/rbc_mainboard/rbc_mainboard.dts:160 */
		};

		/* node '/digital_outputs/out_12' defined in rbc_main_zephyr/boards/rbc_mainboard/rbc_mainboard.dts:161 */
		o12: out_12 {
			gpios = < &gpioe 0x2 0x1 >; /* in rbc_main_zephyr/boards/rbc_mainboard/rbc_mainboard.dts:161 */
			label = "O12";              /* in rbc_main_zephyr/boards/rbc_mainboard/rbc_mainboard.dts:161 */
		};

		/* node '/digital_outputs/misc_pb0' defined in rbc_main_zephyr/boards/rbc_mainboard/rbc_mainboard.dts:164 */
		out_pb0: misc_pb0 {
			gpios = < &gpiob 0x0 0x0 >; /* in rbc_main_zephyr/boards/rbc_mainboard/rbc_mainboard.dts:164 */
			label = "PB0 OUT";          /* in rbc_main_zephyr/boards/rbc_mainboard/rbc_mainboard.dts:164 */
		};

		/* node '/digital_outputs/misc_pb2' defined in rbc_main_zephyr/boards/rbc_mainboard/rbc_mainboard.dts:165 */
		out_pb2: misc_pb2 {
			gpios = < &gpiob 0x2 0x0 >; /* in rbc_main_zephyr/boards/rbc_mainboard/rbc_mainboard.dts:165 */
			label = "PB2 OUT";          /* in rbc_main_zephyr/boards/rbc_mainboard/rbc_mainboard.dts:165 */
		};

		/* node '/digital_outputs/misc_pb12' defined in rbc_main_zephyr/boards/rbc_mainboard/rbc_mainboard.dts:166 */
		out_pb12: misc_pb12 {
			gpios = < &gpiob 0xc 0x0 >; /* in rbc_main_zephyr/boards/rbc_mainboard/rbc_mainboard.dts:166 */
			label = "PB12 OUT";         /* in rbc_main_zephyr/boards/rbc_mainboard/rbc_mainboard.dts:166 */
		};

		/* node '/digital_outputs/misc_pb13' defined in rbc_main_zephyr/boards/rbc_mainboard/rbc_mainboard.dts:167 */
		out_pb13: misc_pb13 {
			gpios = < &gpiob 0xd 0x0 >; /* in rbc_main_zephyr/boards/rbc_mainboard/rbc_mainboard.dts:167 */
			label = "PB13 OUT";         /* in rbc_main_zephyr/boards/rbc_mainboard/rbc_mainboard.dts:167 */
		};

		/* node '/digital_outputs/misc_pc4' defined in rbc_main_zephyr/boards/rbc_mainboard/rbc_mainboard.dts:168 */
		out_pc4: misc_pc4 {
			gpios = < &gpioc 0x4 0x0 >; /* in rbc_main_zephyr/boards/rbc_mainboard/rbc_mainboard.dts:168 */
			label = "PC4 OUT";          /* in rbc_main_zephyr/boards/rbc_mainboard/rbc_mainboard.dts:168 */
		};

		/* node '/digital_outputs/misc_pc5' defined in rbc_main_zephyr/boards/rbc_mainboard/rbc_mainboard.dts:169 */
		out_pc5: misc_pc5 {
			gpios = < &gpioc 0x5 0x0 >; /* in rbc_main_zephyr/boards/rbc_mainboard/rbc_mainboard.dts:169 */
			label = "PC5 OUT";          /* in rbc_main_zephyr/boards/rbc_mainboard/rbc_mainboard.dts:169 */
		};
	};

	/* node '/st7735_ctrl' defined in rbc_main_zephyr/boards/rbc_mainboard/rbc_mainboard.dts:177 */
	st7735_ctrl {
		compatible = "gpio-leds"; /* in rbc_main_zephyr/boards/rbc_mainboard/rbc_mainboard.dts:178 */

		/* node '/st7735_ctrl/lcd_rst' defined in rbc_main_zephyr/boards/rbc_mainboard/rbc_mainboard.dts:179 */
		mh_rst: lcd_rst {
			gpios = < &gpiod 0x2 0x1 >; /* in rbc_main_zephyr/boards/rbc_mainboard/rbc_mainboard.dts:179 */
			label = "LCD RST";          /* in rbc_main_zephyr/boards/rbc_mainboard/rbc_mainboard.dts:179 */
		};

		/* node '/st7735_ctrl/lcd_cs' defined in rbc_main_zephyr/boards/rbc_mainboard/rbc_mainboard.dts:180 */
		mh_cs: lcd_cs {
			gpios = < &gpiod 0x3 0x1 >; /* in rbc_main_zephyr/boards/rbc_mainboard/rbc_mainboard.dts:180 */
			label = "LCD CS";           /* in rbc_main_zephyr/boards/rbc_mainboard/rbc_mainboard.dts:180 */
		};

		/* node '/st7735_ctrl/lcd_dc' defined in rbc_main_zephyr/boards/rbc_mainboard/rbc_mainboard.dts:181 */
		mh_dc: lcd_dc {
			gpios = < &gpiod 0x4 0x0 >; /* in rbc_main_zephyr/boards/rbc_mainboard/rbc_mainboard.dts:181 */
			label = "LCD DC";           /* in rbc_main_zephyr/boards/rbc_mainboard/rbc_mainboard.dts:181 */
		};
	};
};
